VERSION ""

NS_ :

BS_:

BU_: EDS_F

VAL_TABLE_ Rolling_Counter_0x176 15 "Invalid";
VAL_TABLE_ BMS_HVLinkVol_MEAS 65535 "Invalid";
VAL_TABLE_ BMS_HVPackVol_MEAS 65535 "Invalid";
VAL_TABLE_ Rolling_Counter_0x215 15 "Invalid";
VAL_TABLE_ BMS_HWCrash_Sts 1 "Crash " 0 "No Crash";
VAL_TABLE_ BMS_HVIL_STS 2 "short to ground" 1 "Open & short to battery" 0 "Closed";
VAL_TABLE_ BMS_IGN_Sts 1 "ON " 0 "OFF";
VAL_TABLE_ BMS_Sys_STS 8 "Invalid" 7 "Failure, unable to operate" 6 "BCU Sleep mode" 5 "Successful Power Down" 4 "Power Down process" 3 "Successful Power Down of HV" 2 "Successful High Voltage Power Up" 1 "Self-check passes, can be high-voltage" 0 "Initialization of power on, self-checking";
VAL_TABLE_ BMS_HVOnOff_STS 3 "Fail to HV on " 2 "HV On " 1 "Precharge " 0 "HV Off";
VAL_TABLE_ BMS_Balance_STS 1 "active " 0 "Inactive";
VAL_TABLE_ BMS_BatBalance_ERR 1 "normal " 0 "Error";
VAL_TABLE_ BMS_ISU_Status 3 "Level3(<100 Ohms/V)" 2 "Level2(<200 Ohms/V)" 1 "Level1 <500 Ohms/V ~ >200 Ohms/V" 0 "Normal (> 500 Ohms/V)";
VAL_TABLE_ BMS_ERR_LEV 7 "Battery locked -Reserved" 6 "Fault, needs Shutdown and Wakeup" 5 "Emergency off condition" 4 "Delayed power down with FTTI" 3 "Power down without FTTI" 2 "Limp Home" 1 " Warning (any warning in system)" 0 "No error";
VAL_TABLE_ BMS_HV_Sts 4 "AC Charging" 3 "DC Charging" 2 "HV ON" 1 "Precharge" 0 "HV Off";
VAL_TABLE_ Rolling_Counter_0x375 15 "Invalid";
VAL_TABLE_ BMS_MainPosRelay_ERR 1 "normal " 0 "Error";
VAL_TABLE_ BMS_MainPosRelay_STS 4 "stuck open" 3 "stuck closed" 2 "closed" 1 "open" 0 "reserved";
VAL_TABLE_ BMS_PreChgRelay_ERR 1 "normal " 0 "error";
VAL_TABLE_ BMS_PreChgRelay_STS 4 "stuck open" 3 "stuck closed" 2 "closed" 1 "open" 0 "reserved";
VAL_TABLE_ BMS_TotalNegRelay_STS 4 "stuck open" 3 "stuck closed" 2 "closed" 1 "open" 0 "reserved";
VAL_TABLE_ BMS_TotalNegRelay_ERR 1 "normal " 0 "Error";
VAL_TABLE_ EDS_bus_Volt_FWD 16383 "Invalid";
VAL_TABLE_ EDS_bus_Curr_FWD 65535 "Invalid";
VAL_TABLE_ EDS_HVIL_STS_FWD 3 "short to ground" 2 "short to battery" 1 "Open" 0 "Closed";
VAL_TABLE_ Rolling_Counter_0x1F8 15 "Invalid";
VAL_TABLE_ EDS_output_trq_FR 65535 "Invalid";
VAL_TABLE_ EDS_output_trqValid_FR 1 "valid" 0 "invalid";
VAL_TABLE_ EDS_Spd_FR 65535 "Invalid";
VAL_TABLE_ EDS_SpdValid_FR 1 "valid" 0 "invalid";
VAL_TABLE_ EDS_MotorDriveSts_FR 3 "Invaild" 2 "regen control" 1 "Drive control" 0 "Zero control";
VAL_TABLE_ EDS_Work_STS_FR 15 "invaild" 14 "power off" 13 "Failure" 12 "after run" 11 "shut down" 5 "HVReady" 4 "normal" 3 "precharge" 2 "standby" 1 "init" 0 "default";
VAL_TABLE_ EDS_powoff_req_FR 1 "(Request high voltage power down)" 0 "(No request)";
VAL_TABLE_ Rolling_Counter_0x2A8 15 "Invalid";
VAL_TABLE_ EDS_MotorSerialNum_FWD 0 "Invalid";
VAL_TABLE_ EDS_MinTrq_FWD 65535 "Invalid";
VAL_TABLE_ EDS_MaxTrq_FWD 65535 "Invalid";
VAL_TABLE_ EDS_MotTemp_MEAS_EDS_FWD 255 "Invalid";
VAL_TABLE_ EDS_MotTemp_MEAS_EDS_valid_FWD 1 "valid" 0 "invalid";
VAL_TABLE_ EDS_temp_FWD 255 "Invalid";
VAL_TABLE_ EDS_tempValid_FWD 1 "valid" 0 "invalid";
VAL_TABLE_ EDS_disxhg_st_FWD 3 "Finished Active Discharge" 2 "Failed Active Discharge" 1 "Active Discharge" 0 "No Active Discharge";
VAL_TABLE_ EDS_IGBTState_FWD 0 "FreeWheel" 1 "Up Bridge ASC" 2 "Down Bridge ASC" 3 "Normal Run";
VAL_TABLE_ EDS_DampingState_FWD 0 "Damping disable" 1 "Damping active";
VAL_TABLE_ EDS_CoolFlowrate_DMD_FWD 255 "Invalid";
VAL_TABLE_ EDS_FailGrade_ERR_FWD 7 "Invaild" 6 "Invaild" 5 "Fifth Fault,Delayed power off" 4 "Forth Fault,ZeroTorque" 3 "Third Fault,Limp" 2 "Second Fault，Limited power" 1 "First-Level warning" 0 "No fault";
VAL_TABLE_ EDS_MotOverTempAlarm_FWD 1 "Error" 0 "Normal";
VAL_TABLE_ EDS_MotOverTempFault_FWD 1 "Error" 0 "Normal";
VAL_TABLE_ EDS_MotTempSenFault_FWD 1 "Error" 0 "Normal";
VAL_TABLE_ EDS_EDSOverTempUFault_FWD 1 "Error" 0 "Normal";
VAL_TABLE_ EDS_EDSOverTempVFault_FWD 1 "Error" 0 "Normal";
VAL_TABLE_ EDS_EDSOverTempWFault_FWD 1 "Error" 0 "Normal";
VAL_TABLE_ EDS_EDSOverTempAlarm_FWD 1 "Error" 0 "Normal";
VAL_TABLE_ EDS_TCoolantOvHi_FWD 1 "Error" 0 "Normal";
VAL_TABLE_ EDS_EDSTempCmpAlarm_FWD 1 "Error" 0 "Normal";
VAL_TABLE_ EDS_EDSPhaOvCurentHWFault_FWD 1 "Error" 0 "Normal";
VAL_TABLE_ EDS_EDSphaOffCalFault_FWD 1 "Error" 0 "Normal";
VAL_TABLE_ EDS_EDSOverIdcLnkAlarm_FWD 1 "Error" 0 "Normal";
VAL_TABLE_ EDS_EDSHVOverVoltageAlarm_FWD 1 "Error" 0 "Normal";
VAL_TABLE_ EDS_EDSHVOverVoltageFault_FWD 1 "Error" 0 "Normal";
VAL_TABLE_ EDS_EDSHVUnderVoltageAlarm_FWD 1 "Error" 0 "Normal";
VAL_TABLE_ EDS_EDSHVUnderVoltageFault_FWD 1 "Error" 0 "Normal";
VAL_TABLE_ EDS_RunToDischaErr_FWD 1 "Error" 0 "Normal";
VAL_TABLE_ EDS_12VOverVoltageAlarm_FWD 1 "Error" 0 "Normal";
VAL_TABLE_ EDS_12VUnderVoltageAlarm_FWD 1 "Error" 0 "Normal";
VAL_TABLE_ EDS_MotOverAlarm_FWD 1 "Error" 0 "Normal";
VAL_TABLE_ EDS_MotOverFault_FWD 1 "Error" 0 "Normal";
VAL_TABLE_ EDS_iDcLnkOvCLimFail_FWD 1 "Error" 0 "Normal";
VAL_TABLE_ EDS_MotBlockedFault_FWD 1 "Error" 0 "Normal";
VAL_TABLE_ EDS_RSLErr_FWD 1 "Error" 0 "Normal";
VAL_TABLE_ EDS_MotTrqLimFault_FWD 1 "Error" 0 "Normal";
VAL_TABLE_ EDS_ResolverOffsetAngle_FWD 1 "Error" 0 "Normal";
VAL_TABLE_ EDS_EDSDisChgFault_FWD 1 "Error" 0 "Normal";
VAL_TABLE_ EDS_IGBTFault_FWD 1 "Error" 0 "Normal";
VAL_TABLE_ EDS_CANBusoffFault_FWD 1 "Error" 0 "Normal";
VAL_TABLE_ EDS_TDrvBoardOvHiWarn_FWD 1 "Error" 0 "Normal";
VAL_TABLE_ EDS_TIGBTOvHiFault_FWD 1 "Error" 0 "Normal";
VAL_TABLE_ EDS_TIGBTOvHiWarn_FWD 1 "Error" 0 "Normal";
VAL_TABLE_ EDS_IOHWABSampFail_FWD 1 "Error" 0 "Normal";
VAL_TABLE_ EDS_EDSOpenFault_FWD 1 "Error" 0 "Normal";
VAL_TABLE_ EDS_MotorOpenFault_FWD 1 "Error" 0 "Normal";
VAL_TABLE_ EDS_EmacBlkdWarn_FWD 1 "Error" 0 "Normal";
VAL_TABLE_ EDS_VerMatchFailureErr_FWD 1 "Error" 0 "Normal";
VAL_TABLE_ EDS_DiashCirNoPsblErr_FWD 1 "Error" 0 "Normal";
VAL_TABLE_ EDS_OperOutdRngErr_FWD 1 "Error" 0 "Normal";
VAL_TABLE_ EDS_PhaseLossFaultErr_FWD 1 "Error" 0 "Normal";
VAL_TABLE_ EDS_CPLDFault_FWD 1 "Error" 0 "Normal";
VAL_TABLE_ EDS_CPLDFaultBaseSpd_FWD 1 "Error" 0 "Normal";
VAL_TABLE_ EDS_IOHWABNen33Fail_FWD 1 "Error" 0 "Normal";
VAL_TABLE_ EDS_HvMcuSlightFault_RWD 1 "Error" 0 "Normal";
VAL_TABLE_ EDS_HvMcuSevFault_FWD 1 "Error" 0 "Normal";
VAL_TABLE_ EDS_EDSPhaSampHWFault_FWD 1 "Error" 0 "Normal";
VAL_TABLE_ EDS_IsOvHiErr_FWD 1 "Error" 0 "Normal";
VAL_TABLE_ EDS_CanRollingCounterErr_FWD 1 "Error" 0 "Normal";
VAL_TABLE_ EDS_CanTimeoutErr_FWD 1 "Error" 0 "Normal";
VAL_TABLE_ EDS_CrashFault_FWD 1 "Error" 0 "Normal";
VAL_TABLE_ Rolling_Counter_0x229 15 "Invalid";
VAL_TABLE_ VCU_EDS_TargetTqMin_FWD 1023 "Invalid";
VAL_TABLE_ VCU_EDS_StsModeReq_FWD 15 "invaild" 14 "power off" 13 "Failure" 12 "after run" 11 "shut down" 5 "HVReady" 4 "normal" 3 "precharge" 2 "standby" 1 "init" 0 "default";
VAL_TABLE_ VCU_EDS_demtrq_FWD 4095 "Invalid";
VAL_TABLE_ VCU_EDS_demtrqValid_FWD 0 "Valid" 1 "Invalid";
VAL_TABLE_ VCU_EDS_TargetTqMax_FWD 1023 "Invalid";
VAL_TABLE_ VCU_EDS_CreepFlg_FWD 1 "Enable" 0 "Disable";
VAL_TABLE_ VCU_EDS_HILLHoldFlg_FWD 1 "Enable" 0 "Disable";
VAL_TABLE_ VCU_PTC_RelaySts 1 "close" 0 "open";
VAL_TABLE_ VCU_EACEnbReq 1 "Enable" 0 "Disable";
VAL_TABLE_ VCU_EACAllowedPower 1023 "Invalid";
VAL_TABLE_ VCU_EAC_CompSpdReq 16383 "Invaild";
VAL_TABLE_ Rolling_Counter_0x20C 15 "Invalid";
VAL_TABLE_ IPC_ODO 1048575 "Invalid";
VAL_TABLE_ IPC_TripA 65535 "Invalid";
VAL_TABLE_ IPC_AverageSpeedTripA 4095 "Invalid";
VAL_TABLE_ IPC_AverageConsumptionTripA 1023 "Invalid";
VAL_TABLE_ IPC_ParkBrakeSts 3 "Invalid" 2 "Reserved" 1 "Applied" 0 "Released";
VAL_TABLE_ IPC_VehSpd 32767 "Invalid";
VAL_TABLE_ IPC_Sec 63 "Invalid";
VAL_TABLE_ IPC_Min 63 "Invalid";
VAL_TABLE_ IPC_Hour 31 "Invalid";
VAL_TABLE_ IPC_Day 31 "Invalid";
VAL_TABLE_ IPC_Month 15 "Invalid";
VAL_TABLE_ IPC_Year 255 "Invalid";
VAL_TABLE_ IPC_SelfCheckStatus 1 "self-check finish" 0 "self-checking";
VAL_TABLE_ Rolling_Counter_0x432 15 "Invalid";
VAL_TABLE_ MHU_FOTA_State 0 "INIT" 1 "NORMAL" 2 "FOTA FLASHING" 3 "FOTA-SUSPENDED" 4 "FAIL-SAFE-ERROR" 5 "SHUTDOWN" 6 "REMOTE DIAGNOSTICS" 7 "Invalid";
VAL_TABLE_ CCU_TemperatureGearSts 63 "Invalid" 16 "level 8" 15 "level 7" 14 "level 6" 13 "level 5" 12 "level 4" 11 "level 3" 10 "level 2" 9 "level 1" 8 "level 8" 7 "level 7" 6 "level 6" 5 "level 5" 4 "level 4" 3 "level 3" 2 "level 2" 1 "level 1" 0 "Inactive";
VAL_TABLE_ CCU_BlowMode_Sts 7 "Invalid" 6 "Reserve" 4 "Foot and window" 3 "Foot" 2 "Foot and Face" 1 "Face" 0 "OFF";
VAL_TABLE_ CCU_Circulation_Sts 1 "Internal circulation" 0 "Outer circulation";
VAL_TABLE_ CCU_AC_Req 3 "Invalid" 2 "Reserved" 1 "Requset" 0 "No requset";
VAL_TABLE_ CCU_AC_Sts 1 "ON" 0 "OFF";
VAL_TABLE_ CCU_BlowerLevelSts 8 "level 8" 7 "level 7" 6 "level 6" 5 "level 5" 4 "level 4" 3 "level 3" 2 "level 2" 1 "level 1" 0 "OFF";
VAL_TABLE_ CCU_FrontDefrostSts 1 "On" 0 "Off";
VAL_TABLE_ CCU_PTC_Req 3 "Invalid" 2 "Reserved" 1 "Requset" 0 "No requset";
VAL_TABLE_ CCU_PTC_Temperature 1023 "Invaild";
VAL_TABLE_ CCU_CompSpdMEAS_Comp 8191 "Invalid";
VAL_TABLE_ CCU_PollutionSts 1 "ON" 0 "OFF";
VAL_TABLE_ CCU_ExternalTemperature 255 "Invaild";
VAL_TABLE_ CCU_evaporator_Temperature 31 "Invalid";
VAL_TABLE_ CCU_ExternalTemperatureFailSts 1 "invalid" 0 "valid";
VAL_TABLE_ Rolling_Counter_0x112 15 "Invalid";
VAL_TABLE_ STAT_Terminal 7 "Signal invalid" 6 "Reserved" 5 "Reserved" 4 "SW update OTA (Not used in VFe34)" 3 "Engine start (eMotor running)" 2 "ON (Driver Present)" 1 "ACC (Park)" 0 "OFF(Comfort Enable)";
VAL_TABLE_ STAT_CL30s_L_Reserved 3 "Signal invalid" 2 "Failure" 1 "ON" 0 "OFF";
VAL_TABLE_ Rolling_Counter_0x10a 15 "Invalid";
VAL_TABLE_ BCM_LVTop_up 1 "start Top up" 0 "stop Top up";
VAL_TABLE_ Rolling_Counter_0x85 15 "Invalid";
VAL_TABLE_ ACM_Crash_Sts 3 "Invalid Value" 2 "Invalid Value" 1 "Crash_Detected" 0 "No_Event";
VAL_TABLE_ ACM_Airbag_Deployment_Status 3 "Invalid Value" 2 "Invalid Value" 1 "Airbag_Deployment" 0 "No_Airbag_Deployment";
VAL_TABLE_ ACM_Crash_Intensity 7 "Invalid_Value" 6 "Invalid_Value" 5 "Invalid_Value" 4 "Invalid_Value" 3 "Crash_Intensity_3" 2 "Crash_Intensity_2" 1 "Crash_Intensity_1" 0 "No_Crash";
VAL_TABLE_ ACM_Front_Crash 3 "Invalid Value" 2 "Invalid Value" 1 "Front_Crash_Detected" 0 "No_Event";
VAL_TABLE_ ACM_DriverSide_Crash 3 "Invalid Value" 2 "Invalid Value" 1 "Driverside_Crash_Detected" 0 "No_Event";
VAL_TABLE_ ACM_PassSide_Crash 3 "Invalid Value" 2 "Invalid Value" 1 "PassSide_Crash_Detected" 0 "No_Event";
VAL_TABLE_ ACM_Rear_Crash 3 "Invalid Value" 2 "Invalid Value" 1 "Rear_Crash_Detected" 0 "No_Event";
VAL_TABLE_ ACM_Rollover_Crash 3 "Invalid Value" 2 "Invalid Value" 1 "Rollover_Crash_Detected" 0 "No_Event";
VAL_TABLE_ Rolling_Counter_0x342 15 "Invalid";
VAL_TABLE_ ABS_LRWhlSpdRaw 32767 "Invalid";
VAL_TABLE_ ABS_LRWhlSpdRawValid 1 "Valid" 0 "Invalid";
VAL_TABLE_ ABS_RRWhlSpdRaw 32767 "Invalid";
VAL_TABLE_ ABS_RRWhlSpdRawValid 1 "Valid" 0 "Invalid";
VAL_TABLE_ ABS_VehSpd 32767 "Invalid";
VAL_TABLE_ ABS_VehSpdValid 1 "Valid" 0 "Invalid";
VAL_TABLE_ RollingCounter_0x95 15 "Invalid";
VAL_TABLE_ ABS_Active 3 "Signal invalid" 2 "Reserved" 1 "Active" 0 "Inactive";
VAL_TABLE_ ASR_Active 3 "Signal invalid" 2 "Reserved" 1 "Active" 0 "Inactive";
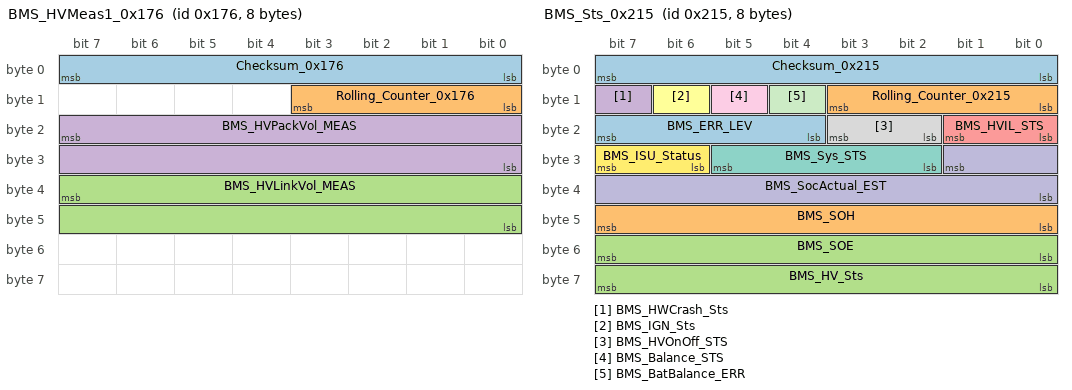
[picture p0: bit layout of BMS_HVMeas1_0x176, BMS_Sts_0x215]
BO_ 374 BMS_HVMeas1_0x176: 8 Vector__XXX
 SG_ Checksum_0x176 : 7|8@0+ (1,0) [0|255] "" EDS_F
 SG_ Rolling_Counter_0x176 : 11|4@0+ (1,0) [0|15] "" EDS_F
 SG_ BMS_HVLinkVol_MEAS : 39|16@0+ (0.1,0) [0|800] "V" Vector__XXX
 SG_ BMS_HVPackVol_MEAS : 23|16@0+ (0.1,0) [0|800] "V" EDS_F
BO_ 533 BMS_Sts_0x215: 8 Vector__XXX
 SG_ Checksum_0x215 : 7|8@0+ (1,0) [0|255] "" EDS_F
 SG_ Rolling_Counter_0x215 : 11|4@0+ (1,0) [0|15] "" EDS_F
 SG_ BMS_SOE : 55|8@0+ (0.5,0) [0|100] "%" Vector__XXX
 SG_ BMS_HWCrash_Sts : 15|1@0+ (1,0) [0|1] "" Vector__XXX
 SG_ BMS_HVIL_STS : 17|2@0+ (1,0) [0|3] "" EDS_F
 SG_ BMS_IGN_Sts : 14|1@0+ (1,0) [0|1] "" EDS_F
 SG_ BMS_Sys_STS : 29|4@0+ (1,0) [0|15] "" EDS_F
 SG_ BMS_HVOnOff_STS : 19|2@0+ (1,0) [0|3] "" EDS_F
 SG_ BMS_Balance_STS : 13|1@0+ (1,0) [0|1] "" EDS_F
 SG_ BMS_SocActual_EST : 25|10@0+ (0.1,0) [0|100] "percent" EDS_F
 SG_ BMS_BatBalance_ERR : 12|1@0+ (1,0) [0|1] "" EDS_F
 SG_ BMS_ISU_Status : 31|2@0+ (1,0) [0|3] "" EDS_F
 SG_ BMS_ERR_LEV : 23|4@0+ (1,0) [0|15] "" EDS_F
 SG_ BMS_SOH : 47|8@0+ (0.5,0) [0|100] "%" EDS_F
 SG_ BMS_HV_Sts : 63|8@0+ (1,0) [0|255] "" Vector__XXX
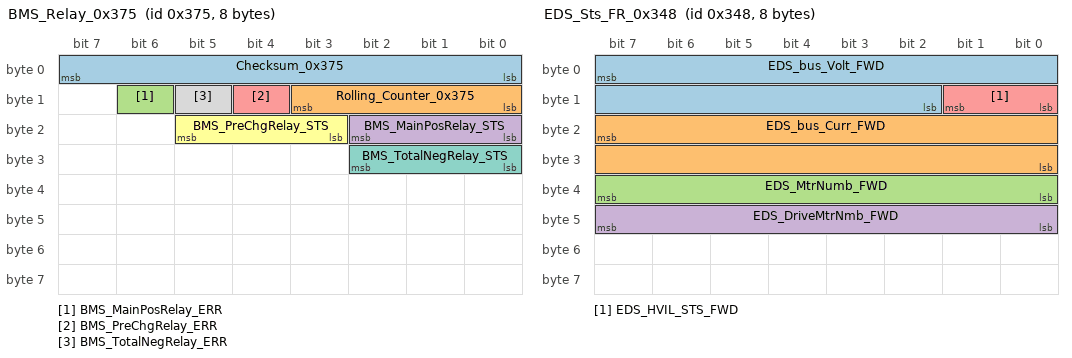
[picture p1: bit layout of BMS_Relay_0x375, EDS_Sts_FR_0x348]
BO_ 885 BMS_Relay_0x375: 8 Vector__XXX
 SG_ Checksum_0x375 : 7|8@0+ (1,0) [0|255] "" EDS_F
 SG_ Rolling_Counter_0x375 : 11|4@0+ (1,0) [0|15] "" EDS_F
 SG_ BMS_MainPosRelay_ERR : 14|1@0+ (1,0) [0|1] "" EDS_F
 SG_ BMS_MainPosRelay_STS : 18|3@0+ (1,0) [0|7] "" EDS_F
 SG_ BMS_PreChgRelay_ERR : 12|1@0+ (1,0) [0|1] "" Vector__XXX
 SG_ BMS_PreChgRelay_STS : 21|3@0+ (1,0) [0|7] "" Vector__XXX
 SG_ BMS_TotalNegRelay_STS : 26|3@0+ (1,0) [0|7] "" Vector__XXX
 SG_ BMS_TotalNegRelay_ERR : 13|1@0+ (1,0) [0|1] "" Vector__XXX
BO_ 840 EDS_Sts_FR_0x348: 8 EDS_F
 SG_ EDS_bus_Volt_FWD : 7|14@0+ (0.1,0) [0|1000] "V" Vector__XXX
 SG_ EDS_bus_Curr_FWD : 23|16@0+ (0.1,-1000) [-1000|1000] "A" Vector__XXX
 SG_ EDS_MtrNumb_FWD : 39|8@0+ (1,0) [0|255] "" Vector__XXX
 SG_ EDS_DriveMtrNmb_FWD : 47|8@0+ (1,0) [0|255] "" Vector__XXX
 SG_ EDS_HVIL_STS_FWD : 9|2@0+ (1,0) [0|3] "" Vector__XXX
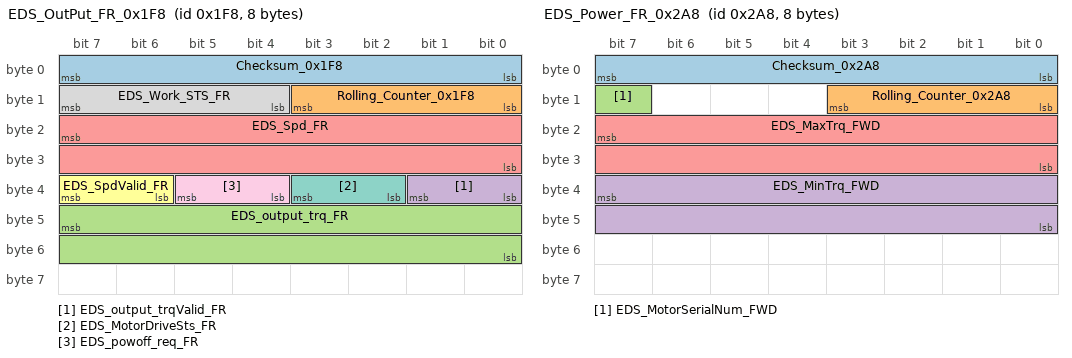
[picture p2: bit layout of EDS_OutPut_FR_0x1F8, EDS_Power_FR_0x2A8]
BO_ 504 EDS_OutPut_FR_0x1F8: 8 EDS_F
 SG_ Checksum_0x1F8 : 7|8@0+ (1,0) [0|255] "" Vector__XXX
 SG_ Rolling_Counter_0x1F8 : 11|4@0+ (1,0) [0|15] "" Vector__XXX
 SG_ EDS_output_trq_FR : 47|16@0+ (1,-2000) [-2000|2000] "Nm" Vector__XXX
 SG_ EDS_output_trqValid_FR : 33|2@0+ (1,0) [0|1] "" Vector__XXX
 SG_ EDS_Spd_FR : 23|16@0+ (1,-20000) [-20000|20000] "rpm" Vector__XXX
 SG_ EDS_SpdValid_FR : 39|2@0+ (1,0) [0|1] "" Vector__XXX
 SG_ EDS_MotorDriveSts_FR : 35|2@0+ (1,0) [0|3] "" Vector__XXX
 SG_ EDS_Work_STS_FR : 15|4@0+ (1,0) [0|15] "" Vector__XXX
 SG_ EDS_powoff_req_FR : 37|2@0+ (1,0) [0|1] "" Vector__XXX
BO_ 680 EDS_Power_FR_0x2A8: 8 EDS_F
 SG_ Checksum_0x2A8 : 7|8@0+ (1,0) [0|255] "" Vector__XXX
 SG_ Rolling_Counter_0x2A8 : 11|4@0+ (1,0) [0|15] "" Vector__XXX
 SG_ EDS_MotorSerialNum_FWD : 15|1@0+ (1,0) [0|1] "" Vector__XXX
 SG_ EDS_MinTrq_FWD : 39|16@0+ (1,-2000) [-2000|2000] "Nm" Vector__XXX
 SG_ EDS_MaxTrq_FWD : 23|16@0+ (1,-2000) [-2000|2000] "Nm" Vector__XXX
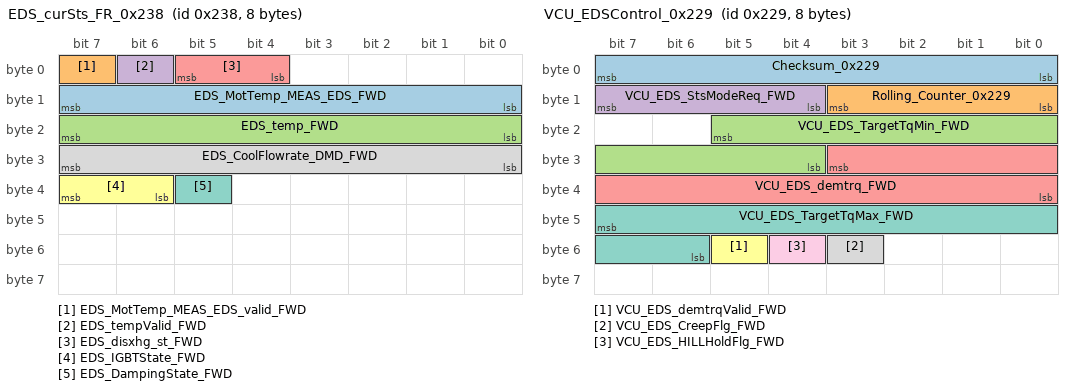
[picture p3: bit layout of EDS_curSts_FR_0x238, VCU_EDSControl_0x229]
BO_ 568 EDS_curSts_FR_0x238: 8 EDS_F
 SG_ EDS_MotTemp_MEAS_EDS_FWD : 15|8@0+ (1,-40) [-40|215] "degree" Vector__XXX
 SG_ EDS_MotTemp_MEAS_EDS_valid_FWD : 7|1@0+ (1,0) [0|1] "" Vector__XXX
 SG_ EDS_temp_FWD : 23|8@0+ (1,-40) [-40|215] "degree" Vector__XXX
 SG_ EDS_tempValid_FWD : 6|1@0+ (1,0) [0|1] "" Vector__XXX
 SG_ EDS_disxhg_st_FWD : 5|2@0+ (1,0) [0|3] "" Vector__XXX
 SG_ EDS_IGBTState_FWD : 39|2@0+ (1,0) [0|3] "" Vector__XXX
 SG_ EDS_DampingState_FWD : 37|1@0+ (1,0) [0|1] "" Vector__XXX
 SG_ EDS_CoolFlowrate_DMD_FWD : 31|8@0+ (0.1,0) [0|25.4] "L/min" Vector__XXX
BO_ 1080 EDS_Error_FR_0x438: 8 EDS_F
 SG_ EDS_FailNum_ERR_FWD : 7|8@0+ (1,0) [0|255] "" Vector__XXX
 SG_ EDS_FailGrade_ERR_FWD : 10|3@0+ (1,0) [0|7] "" Vector__XXX
 SG_ EDS_MotOverTempAlarm_FWD : 11|1@0+ (1,0) [0|1] "" Vector__XXX
 SG_ EDS_MotOverTempFault_FWD : 12|1@0+ (1,0) [0|1] "" Vector__XXX
 SG_ EDS_MotTempSenFault_FWD : 13|1@0+ (1,0) [0|1] "" Vector__XXX
 SG_ EDS_EDSOverTempUFault_FWD : 14|1@0+ (1,0) [0|1] "" Vector__XXX
 SG_ EDS_EDSOverTempVFault_FWD : 15|1@0+ (1,0) [0|1] "" Vector__XXX
 SG_ EDS_EDSOverTempWFault_FWD : 16|1@0+ (1,0) [0|1] "" Vector__XXX
 SG_ EDS_EDSOverTempAlarm_FWD : 17|1@0+ (1,0) [0|1] "" Vector__XXX
 SG_ EDS_TCoolantOvHi_FWD : 18|1@0+ (1,0) [0|1] "" Vector__XXX
 SG_ EDS_EDSTempCmpAlarm_FWD : 19|1@0+ (1,0) [0|1] "" Vector__XXX
 SG_ EDS_EDSPhaOvCurentHWFault_FWD : 20|1@0+ (1,0) [0|1] "" Vector__XXX
 SG_ EDS_EDSphaOffCalFault_FWD : 21|1@0+ (1,0) [0|1] "" Vector__XXX
 SG_ EDS_EDSOverIdcLnkAlarm_FWD : 22|1@0+ (1,0) [0|1] "" Vector__XXX
 SG_ EDS_EDSHVOverVoltageAlarm_FWD : 23|1@0+ (1,0) [0|1] "" Vector__XXX
 SG_ EDS_EDSHVOverVoltageFault_FWD : 24|1@0+ (1,0) [0|1] "" Vector__XXX
 SG_ EDS_EDSHVUnderVoltageAlarm_FWD : 25|1@0+ (1,0) [0|1] "" Vector__XXX
 SG_ EDS_EDSHVUnderVoltageFault_FWD : 26|1@0+ (1,0) [0|1] "" Vector__XXX
 SG_ EDS_RunToDischaErr_FWD : 27|1@0+ (1,0) [0|1] "" Vector__XXX
 SG_ EDS_12VOverVoltageAlarm_FWD : 28|1@0+ (1,0) [0|1] "" Vector__XXX
 SG_ EDS_12VUnderVoltageAlarm_FWD : 29|1@0+ (1,0) [0|1] "" Vector__XXX
 SG_ EDS_MotOverAlarm_FWD : 30|1@0+ (1,0) [0|1] "" Vector__XXX
 SG_ EDS_MotOverFault_FWD : 31|1@0+ (1,0) [0|1] "" Vector__XXX
 SG_ EDS_iDcLnkOvCLimFail_FWD : 32|1@0+ (1,0) [0|1] "" Vector__XXX
 SG_ EDS_MotBlockedFault_FWD : 33|1@0+ (1,0) [0|1] "" Vector__XXX
 SG_ EDS_RSLErr_FWD : 34|1@0+ (1,0) [0|1] "" Vector__XXX
 SG_ EDS_MotTrqLimFault_FWD : 35|1@0+ (1,0) [0|1] "" Vector__XXX
 SG_ EDS_ResolverOffsetAngle_FWD : 36|1@0+ (1,0) [0|1] "" Vector__XXX
 SG_ EDS_EDSDisChgFault_FWD : 37|1@0+ (1,0) [0|1] "" Vector__XXX
 SG_ EDS_IGBTFault_FWD : 38|1@0+ (1,0) [0|1] "" Vector__XXX
 SG_ EDS_CANBusoffFault_FWD : 39|1@0+ (1,0) [0|1] "" Vector__XXX
 SG_ EDS_TDrvBoardOvHiWarn_FWD : 40|1@0+ (1,0) [0|1] "" Vector__XXX
 SG_ EDS_TIGBTOvHiFault_FWD : 41|1@0+ (1,0) [0|1] "" Vector__XXX
 SG_ EDS_TIGBTOvHiWarn_FWD : 42|1@0+ (1,0) [0|1] "" Vector__XXX
 SG_ EDS_IOHWABSampFail_FWD : 43|1@0+ (1,0) [0|1] "" Vector__XXX
 SG_ EDS_EDSOpenFault_FWD : 44|1@0+ (1,0) [0|1] "" Vector__XXX
 SG_ EDS_MotorOpenFault_FWD : 45|1@0+ (1,0) [0|1] "" Vector__XXX
 SG_ EDS_EmacBlkdWarn_FWD : 47|1@0+ (1,0) [0|1] "" Vector__XXX
 SG_ EDS_VerMatchFailureErr_FWD : 48|1@0+ (1,0) [0|1] "" Vector__XXX
 SG_ EDS_DiashCirNoPsblErr_FWD : 49|1@0+ (1,0) [0|1] "" Vector__XXX
 SG_ EDS_OperOutdRngErr_FWD : 50|1@0+ (1,0) [0|1] "" Vector__XXX
 SG_ EDS_PhaseLossFaultErr_FWD : 51|1@0+ (1,0) [0|1] "" Vector__XXX
 SG_ EDS_CPLDFault_FWD : 52|1@0+ (1,0) [0|1] "" Vector__XXX
 SG_ EDS_CPLDFaultBaseSpd_FWD : 53|1@0+ (1,0) [0|1] "" Vector__XXX
 SG_ EDS_IOHWABNen33Fail_FWD : 54|1@0+ (1,0) [0|1] "" Vector__XXX
 SG_ EDS_HvMcuSlightFault_RWD : 55|1@0+ (1,0) [0|1] "" Vector__XXX
 SG_ EDS_HvMcuSevFault_FWD : 56|1@0+ (1,0) [0|1] "" Vector__XXX
 SG_ EDS_EDSPhaSampHWFault_FWD : 57|1@0+ (1,0) [0|1] "" Vector__XXX
 SG_ EDS_IsOvHiErr_FWD : 58|1@0+ (1,0) [0|1] "" Vector__XXX
 SG_ EDS_CanRollingCounterErr_FWD : 59|1@0+ (1,0) [0|1] "" Vector__XXX
 SG_ EDS_CanTimeoutErr_FWD : 60|1@0+ (1,0) [0|1] "" Vector__XXX
 SG_ EDS_CrashFault_FWD : 61|1@0+ (1,0) [0|1] "" Vector__XXX
BO_ 553 VCU_EDSControl_0x229: 8 Vector__XXX
 SG_ Checksum_0x229 : 7|8@0+ (1,0) [0|255] "" EDS_F
 SG_ Rolling_Counter_0x229 : 11|4@0+ (1,0) [0|15] "" EDS_F
 SG_ VCU_EDS_TargetTqMin_FWD : 21|10@0+ (1,-500) [-500|0] "Nm" EDS_F
 SG_ VCU_EDS_StsModeReq_FWD : 15|4@0+ (1,0) [0|15] "" EDS_F
 SG_ VCU_EDS_demtrq_FWD : 27|12@0+ (0.5,-500) [-500|500] "Nm" EDS_F
 SG_ VCU_EDS_demtrqValid_FWD : 53|1@0+ (1,0) [0|1] "" EDS_F
 SG_ VCU_EDS_TargetTqMax_FWD : 47|10@0+ (1,0) [0|500] "Nm" EDS_F
 SG_ VCU_EDS_CreepFlg_FWD : 51|1@0+ (1,0) [0|1] "" Vector__XXX
 SG_ VCU_EDS_HILLHoldFlg_FWD : 52|1@0+ (1,0) [0|1] "" Vector__XXX
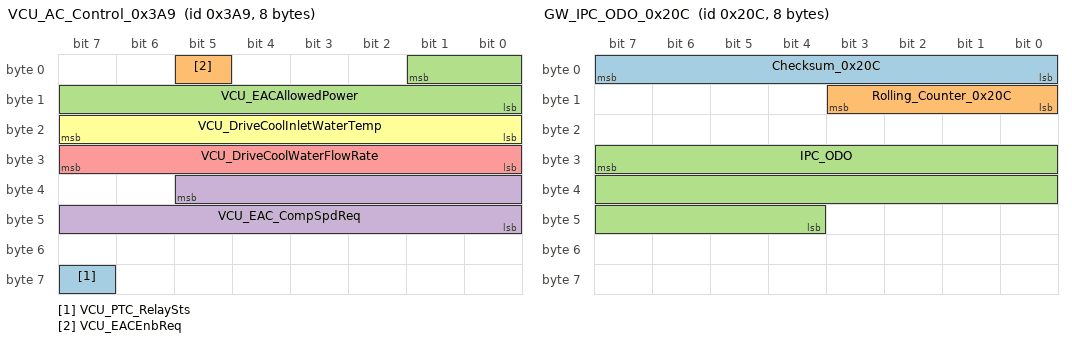
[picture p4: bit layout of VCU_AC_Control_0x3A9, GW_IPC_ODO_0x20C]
BO_ 937 VCU_AC_Control_0x3A9: 8 Vector__XXX
 SG_ VCU_PTC_RelaySts : 63|1@0+ (1,0) [0|1] "" Vector__XXX
 SG_ VCU_EACEnbReq : 5|1@0+ (1,0) [0|1] "" Vector__XXX
 SG_ VCU_EACAllowedPower : 1|10@0+ (0.1,0) [0|100] "KW" Vector__XXX
 SG_ VCU_EAC_CompSpdReq : 37|14@0+ (1,0) [0|16383] "rpm" Vector__XXX
 SG_ VCU_DriveCoolWaterFlowRate : 31|8@0+ (0.1,0) [0|25.4] "L/min" EDS_F
 SG_ VCU_DriveCoolInletWaterTemp : 23|8@0+ (1,-40) [-40|215] "degree" EDS_F
BO_ 524 GW_IPC_ODO_0x20C: 8 Vector__XXX
 SG_ Checksum_0x20C : 7|8@0+ (1,0) [0|255] "" EDS_F
 SG_ Rolling_Counter_0x20C : 11|4@0+ (1,0) [0|15] "" EDS_F
 SG_ IPC_ODO : 31|20@0+ (1,0) [0|999999] "km" EDS_F
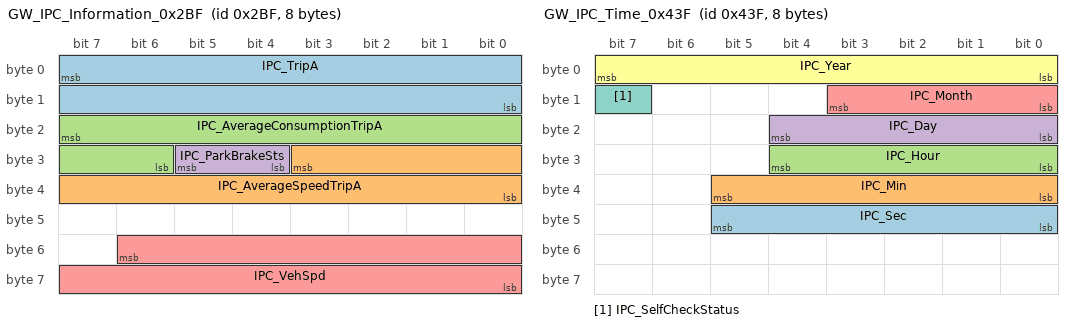
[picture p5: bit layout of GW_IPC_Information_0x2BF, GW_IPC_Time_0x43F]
BO_ 703 GW_IPC_Information_0x2BF: 8 Vector__XXX
 SG_ IPC_TripA : 7|16@0+ (0.1,0) [0|999.9] "km" Vector__XXX
 SG_ IPC_AverageSpeedTripA : 27|12@0+ (0.0625,0) [0|250] "km/h" Vector__XXX
 SG_ IPC_AverageConsumptionTripA : 23|10@0+ (0.1,0) [0|100] "kwh/100km" Vector__XXX
 SG_ IPC_ParkBrakeSts : 29|2@0+ (1,0) [0|3] "" Vector__XXX
 SG_ IPC_VehSpd : 54|15@0+ (0.01,0) [0|327.66] "kph" EDS_F
BO_ 1087 GW_IPC_Time_0x43F: 8 Vector__XXX
 SG_ IPC_Sec : 45|6@0+ (1,0) [0|59] "second" EDS_F
 SG_ IPC_Min : 37|6@0+ (1,0) [0|59] "min" EDS_F
 SG_ IPC_Hour : 28|5@0+ (1,0) [0|23] "hour" EDS_F
 SG_ IPC_Day : 20|5@0+ (1,0) [1|31] "" EDS_F
 SG_ IPC_Month : 11|4@0+ (1,0) [1|12] "" EDS_F
 SG_ IPC_Year : 7|8@0+ (1,2000) [2000|2255] "" EDS_F
 SG_ IPC_SelfCheckStatus : 15|1@0+ (1,0) [0|1] "" EDS_F
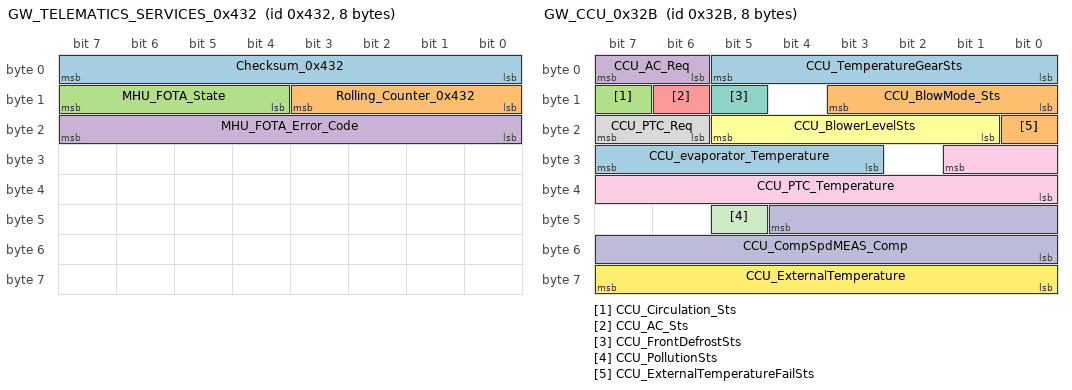
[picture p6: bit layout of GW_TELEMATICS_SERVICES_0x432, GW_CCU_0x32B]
BO_ 1074 GW_TELEMATICS_SERVICES_0x432: 8 Vector__XXX
 SG_ Checksum_0x432 : 7|8@0+ (1,0) [0|255] "" EDS_F
 SG_ Rolling_Counter_0x432 : 11|4@0+ (1,0) [0|14] "" EDS_F
 SG_ MHU_FOTA_State : 15|4@0+ (1,0) [0|14] "" EDS_F
 SG_ MHU_FOTA_Error_Code : 23|8@0+ (1,0) [0|255] "" EDS_F
BO_ 811 GW_CCU_0x32B: 8 Vector__XXX
 SG_ CCU_TemperatureGearSts : 5|6@0+ (1,0) [0|63] "" Vector__XXX
 SG_ CCU_BlowMode_Sts : 11|4@0+ (1,0) [0|15] "" Vector__XXX
 SG_ CCU_Circulation_Sts : 15|1@0+ (1,0) [0|1] "" Vector__XXX
 SG_ CCU_AC_Req : 7|2@0+ (1,0) [0|3] "" Vector__XXX
 SG_ CCU_AC_Sts : 14|1@0+ (1,0) [0|1] "" Vector__XXX
 SG_ CCU_BlowerLevelSts : 21|5@0+ (1,0) [0|9] "" Vector__XXX
 SG_ CCU_FrontDefrostSts : 13|1@0+ (1,0) [0|1] "" Vector__XXX
 SG_ CCU_PTC_Req : 23|2@0+ (1,0) [0|3] "" Vector__XXX
 SG_ CCU_PTC_Temperature : 25|10@0+ (0.1,0) [0|100] "°C" Vector__XXX
 SG_ CCU_CompSpdMEAS_Comp : 44|13@0+ (1,0) [0|8191] "rpm" Vector__XXX
 SG_ CCU_PollutionSts : 45|1@0+ (1,0) [0|1] "" Vector__XXX
 SG_ CCU_ExternalTemperature : 63|8@0+ (0.5,-40) [-40|87] "°C" EDS_F
 SG_ CCU_evaporator_Temperature : 31|5@0+ (1,-10) [-10|20] "°C" Vector__XXX
 SG_ CCU_ExternalTemperatureFailSts : 16|1@0+ (1,0) [0|1] "" EDS_F
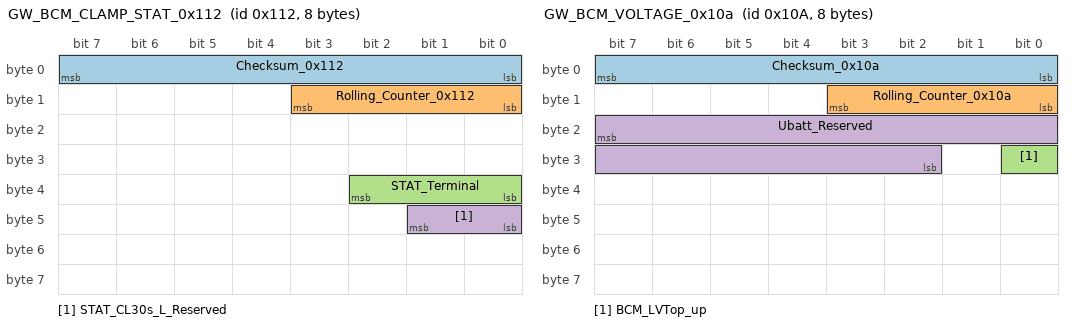
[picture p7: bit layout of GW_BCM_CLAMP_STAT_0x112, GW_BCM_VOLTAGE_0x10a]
BO_ 274 GW_BCM_CLAMP_STAT_0x112: 8 Vector__XXX
 SG_ Checksum_0x112 : 7|8@0+ (1,0) [0|255] "" EDS_F
 SG_ Rolling_Counter_0x112 : 11|4@0+ (1,0) [0|15] "" EDS_F
 SG_ STAT_Terminal : 34|3@0+ (1,0) [0|7] "Bit" EDS_F
 SG_ STAT_CL30s_L_Reserved : 41|2@0+ (1,0) [0|3] "Bit" Vector__XXX
BO_ 266 GW_BCM_VOLTAGE_0x10a: 8 Vector__XXX
 SG_ Checksum_0x10a : 7|8@0+ (1,0) [0|255] "" EDS_F
 SG_ Rolling_Counter_0x10a : 11|4@0+ (1,0) [0|15] "" EDS_F
 SG_ BCM_LVTop_up : 24|1@0+ (1,0) [0|1] "" Vector__XXX
 SG_ Ubatt_Reserved : 23|14@0+ (0.001,3) [3|18] "V" EDS_F
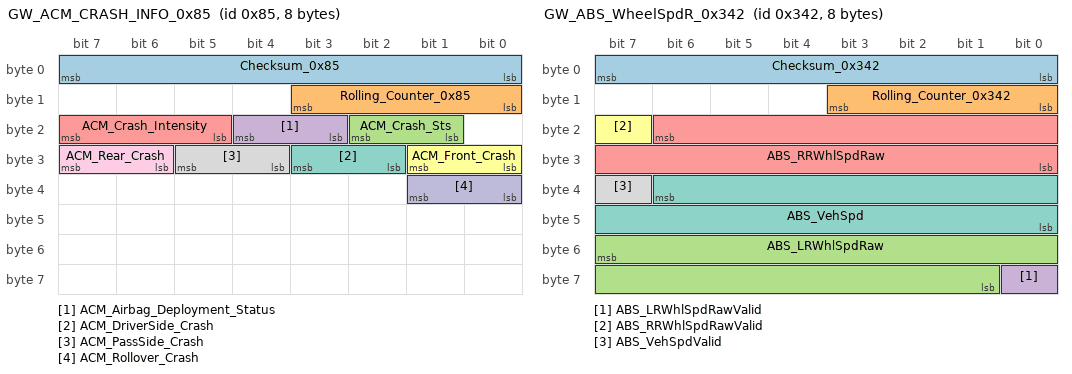
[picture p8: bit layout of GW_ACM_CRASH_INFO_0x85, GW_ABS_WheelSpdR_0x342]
BO_ 133 GW_ACM_CRASH_INFO_0x85: 8 Vector__XXX
 SG_ Checksum_0x85 : 7|8@0+ (1,0) [0|255] "" EDS_F
 SG_ Rolling_Counter_0x85 : 11|4@0+ (1,0) [0|15] "" EDS_F
 SG_ ACM_Crash_Sts : 18|2@0+ (1,0) [0|3] "" EDS_F
 SG_ ACM_Airbag_Deployment_Status : 20|2@0+ (1,0) [0|3] "" Vector__XXX
 SG_ ACM_Crash_Intensity : 23|3@0+ (1,0) [0|7] "" EDS_F
 SG_ ACM_Front_Crash : 25|2@0+ (1,0) [0|3] "" Vector__XXX
 SG_ ACM_DriverSide_Crash : 27|2@0+ (1,0) [0|3] "" Vector__XXX
 SG_ ACM_PassSide_Crash : 29|2@0+ (1,0) [0|3] "" Vector__XXX
 SG_ ACM_Rear_Crash : 31|2@0+ (1,0) [0|3] "" Vector__XXX
 SG_ ACM_Rollover_Crash : 33|2@0+ (1,0) [0|3] "" Vector__XXX
BO_ 834 GW_ABS_WheelSpdR_0x342: 8 Vector__XXX
 SG_ Checksum_0x342 : 7|8@0+ (1,0) [0|255] "" EDS_F
 SG_ Rolling_Counter_0x342 : 11|4@0+ (1,0) [0|15] "" EDS_F
 SG_ ABS_LRWhlSpdRaw : 55|15@0+ (0.01,0) [0|327.66] "kph" Vector__XXX
 SG_ ABS_LRWhlSpdRawValid : 56|1@0+ (1,0) [0|1] "" Vector__XXX
 SG_ ABS_RRWhlSpdRaw : 22|15@0+ (0.01,0) [0|327.66] "kph" Vector__XXX
 SG_ ABS_RRWhlSpdRawValid : 23|1@0+ (1,0) [0|1] "" Vector__XXX
 SG_ ABS_VehSpd : 38|15@0+ (0.01,0) [0|327.66] "kph" EDS_F
 SG_ ABS_VehSpdValid : 39|1@0+ (1,0) [0|1] "" EDS_F
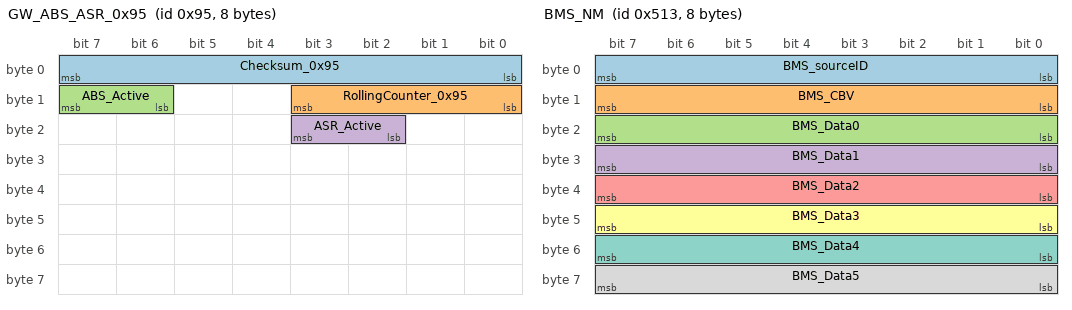
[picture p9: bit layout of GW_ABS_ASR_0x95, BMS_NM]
BO_ 149 GW_ABS_ASR_0x95: 8 Vector__XXX
 SG_ Checksum_0x95 : 7|8@0+ (1,0) [0|255] "" EDS_F
 SG_ RollingCounter_0x95 : 11|4@0+ (1,0) [0|14] "" EDS_F
 SG_ ABS_Active : 15|2@0+ (1,0) [0|3] "" EDS_F
 SG_ ASR_Active : 19|2@0+ (1,0) [0|3] "" EDS_F
BO_ 1299 BMS_NM: 8 Vector__XXX
 SG_ BMS_sourceID : 7|8@0+ (1,0) [0|255] "" EDS_F
 SG_ BMS_CBV : 15|8@0+ (1,0) [0|255] "" EDS_F
 SG_ BMS_Data0 : 23|8@0+ (1,0) [0|255] "" EDS_F
 SG_ BMS_Data1 : 31|8@0+ (1,0) [0|255] "" EDS_F
 SG_ BMS_Data2 : 39|8@0+ (1,0) [0|255] "" EDS_F
 SG_ BMS_Data3 : 47|8@0+ (1,0) [0|255] "" EDS_F
 SG_ BMS_Data4 : 55|8@0+ (1,0) [0|255] "" EDS_F
 SG_ BMS_Data5 : 63|8@0+ (1,0) [0|255] "" EDS_F
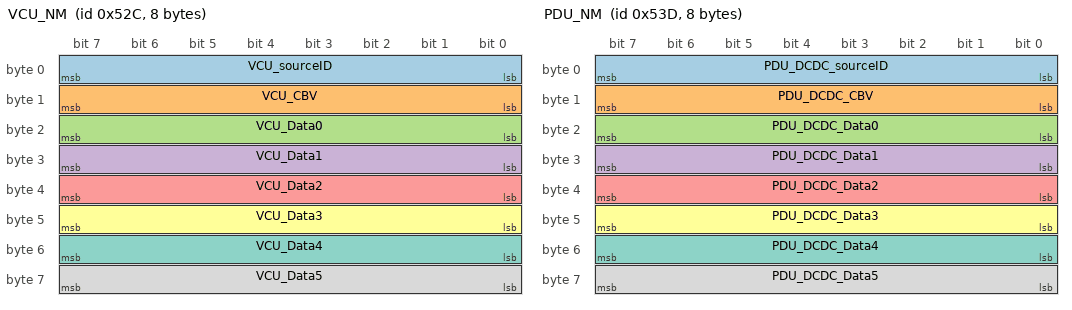
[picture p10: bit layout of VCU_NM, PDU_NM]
BO_ 1324 VCU_NM: 8 Vector__XXX
 SG_ VCU_sourceID : 7|8@0+ (1,0) [0|255] "" EDS_F
 SG_ VCU_CBV : 15|8@0+ (1,0) [0|255] "" EDS_F
 SG_ VCU_Data0 : 23|8@0+ (1,0) [0|255] "" EDS_F
 SG_ VCU_Data1 : 31|8@0+ (1,0) [0|255] "" EDS_F
 SG_ VCU_Data2 : 39|8@0+ (1,0) [0|255] "" EDS_F
 SG_ VCU_Data3 : 47|8@0+ (1,0) [0|255] "" EDS_F
 SG_ VCU_Data4 : 55|8@0+ (1,0) [0|255] "" EDS_F
 SG_ VCU_Data5 : 63|8@0+ (1,0) [0|255] "" EDS_F
BO_ 1341 PDU_NM: 8 Vector__XXX
 SG_ PDU_DCDC_sourceID : 7|8@0+ (1,0) [0|255] "" EDS_F
 SG_ PDU_DCDC_CBV : 15|8@0+ (1,0) [0|255] "" EDS_F
 SG_ PDU_DCDC_Data0 : 23|8@0+ (1,0) [0|255] "" EDS_F
 SG_ PDU_DCDC_Data1 : 31|8@0+ (1,0) [0|255] "" EDS_F
 SG_ PDU_DCDC_Data2 : 39|8@0+ (1,0) [0|255] "" EDS_F
 SG_ PDU_DCDC_Data3 : 47|8@0+ (1,0) [0|255] "" EDS_F
 SG_ PDU_DCDC_Data4 : 55|8@0+ (1,0) [0|255] "" EDS_F
 SG_ PDU_DCDC_Data5 : 63|8@0+ (1,0) [0|255] "" EDS_F
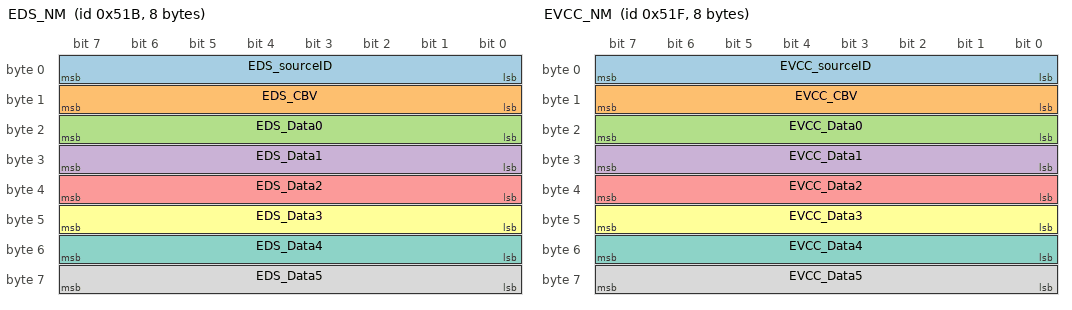
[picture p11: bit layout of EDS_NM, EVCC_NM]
BO_ 1307 EDS_NM: 8 EDS_F
 SG_ EDS_sourceID : 7|8@0+ (1,0) [0|255] "" Vector__XXX
 SG_ EDS_CBV : 15|8@0+ (1,0) [0|255] "" Vector__XXX
 SG_ EDS_Data0 : 23|8@0+ (1,0) [0|255] "" Vector__XXX
 SG_ EDS_Data1 : 31|8@0+ (1,0) [0|255] "" Vector__XXX
 SG_ EDS_Data2 : 39|8@0+ (1,0) [0|255] "" Vector__XXX
 SG_ EDS_Data3 : 47|8@0+ (1,0) [0|255] "" Vector__XXX
 SG_ EDS_Data4 : 55|8@0+ (1,0) [0|255] "" Vector__XXX
 SG_ EDS_Data5 : 63|8@0+ (1,0) [0|255] "" Vector__XXX
BO_ 1311 EVCC_NM: 8 Vector__XXX
 SG_ EVCC_sourceID : 7|8@0+ (1,0) [0|255] "" EDS_F
 SG_ EVCC_CBV : 15|8@0+ (1,0) [0|255] "" EDS_F
 SG_ EVCC_Data0 : 23|8@0+ (1,0) [0|255] "" EDS_F
 SG_ EVCC_Data1 : 31|8@0+ (1,0) [0|255] "" EDS_F
 SG_ EVCC_Data2 : 39|8@0+ (1,0) [0|255] "" EDS_F
 SG_ EVCC_Data3 : 47|8@0+ (1,0) [0|255] "" EDS_F
 SG_ EVCC_Data4 : 55|8@0+ (1,0) [0|255] "" EDS_F
 SG_ EVCC_Data5 : 63|8@0+ (1,0) [0|255] "" EDS_F
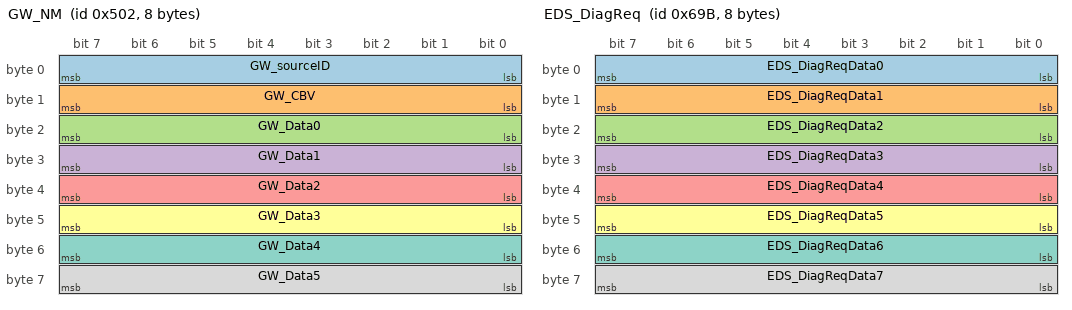
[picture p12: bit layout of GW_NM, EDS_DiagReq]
BO_ 1282 GW_NM: 8 Vector__XXX
 SG_ GW_sourceID : 7|8@0+ (1,0) [0|255] "" EDS_F
 SG_ GW_CBV : 15|8@0+ (1,0) [0|255] "" EDS_F
 SG_ GW_Data0 : 23|8@0+ (1,0) [0|255] "" EDS_F
 SG_ GW_Data1 : 31|8@0+ (1,0) [0|255] "" EDS_F
 SG_ GW_Data2 : 39|8@0+ (1,0) [0|255] "" EDS_F
 SG_ GW_Data3 : 47|8@0+ (1,0) [0|255] "" EDS_F
 SG_ GW_Data4 : 55|8@0+ (1,0) [0|255] "" EDS_F
 SG_ GW_Data5 : 63|8@0+ (1,0) [0|255] "" EDS_F
BO_ 1691 EDS_DiagReq: 8 Vector__XXX
 SG_ EDS_DiagReqData0 : 7|8@0+ (1,0) [0|255] "" EDS_F
 SG_ EDS_DiagReqData1 : 15|8@0+ (1,0) [0|255] "" EDS_F
 SG_ EDS_DiagReqData2 : 23|8@0+ (1,0) [0|255] "" EDS_F
 SG_ EDS_DiagReqData3 : 31|8@0+ (1,0) [0|255] "" EDS_F
 SG_ EDS_DiagReqData4 : 39|8@0+ (1,0) [0|255] "" EDS_F
 SG_ EDS_DiagReqData5 : 47|8@0+ (1,0) [0|255] "" EDS_F
 SG_ EDS_DiagReqData6 : 55|8@0+ (1,0) [0|255] "" EDS_F
 SG_ EDS_DiagReqData7 : 63|8@0+ (1,0) [0|255] "" EDS_F
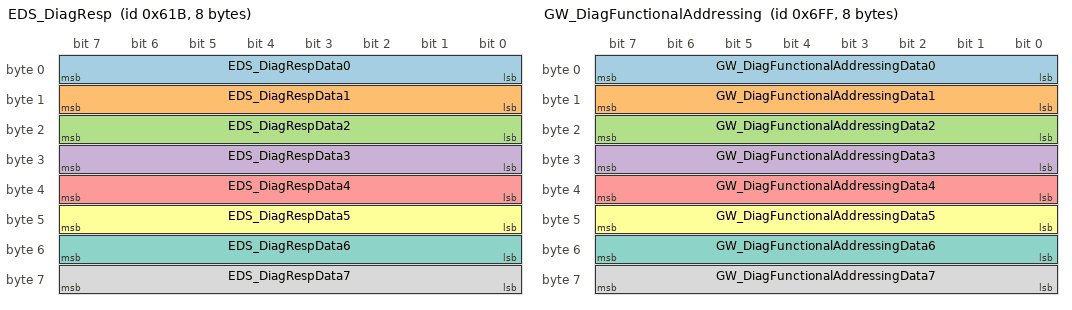
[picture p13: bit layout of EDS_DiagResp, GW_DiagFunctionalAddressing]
BO_ 1563 EDS_DiagResp: 8 EDS_F
 SG_ EDS_DiagRespData0 : 7|8@0+ (1,0) [0|255] "" Vector__XXX
 SG_ EDS_DiagRespData1 : 15|8@0+ (1,0) [0|255] "" Vector__XXX
 SG_ EDS_DiagRespData2 : 23|8@0+ (1,0) [0|255] "" Vector__XXX
 SG_ EDS_DiagRespData3 : 31|8@0+ (1,0) [0|255] "" Vector__XXX
 SG_ EDS_DiagRespData4 : 39|8@0+ (1,0) [0|255] "" Vector__XXX
 SG_ EDS_DiagRespData5 : 47|8@0+ (1,0) [0|255] "" Vector__XXX
 SG_ EDS_DiagRespData6 : 55|8@0+ (1,0) [0|255] "" Vector__XXX
 SG_ EDS_DiagRespData7 : 63|8@0+ (1,0) [0|255] "" Vector__XXX
BO_ 1791 GW_DiagFunctionalAddressing: 8 Vector__XXX
 SG_ GW_DiagFunctionalAddressingData0 : 7|8@0+ (1,0) [0|255] "" EDS_F
 SG_ GW_DiagFunctionalAddressingData1 : 15|8@0+ (1,0) [0|255] "" EDS_F
 SG_ GW_DiagFunctionalAddressingData2 : 23|8@0+ (1,0) [0|255] "" EDS_F
 SG_ GW_DiagFunctionalAddressingData3 : 31|8@0+ (1,0) [0|255] "" EDS_F
 SG_ GW_DiagFunctionalAddressingData4 : 39|8@0+ (1,0) [0|255] "" EDS_F
 SG_ GW_DiagFunctionalAddressingData5 : 47|8@0+ (1,0) [0|255] "" EDS_F
 SG_ GW_DiagFunctionalAddressingData6 : 55|8@0+ (1,0) [0|255] "" EDS_F
 SG_ GW_DiagFunctionalAddressingData7 : 63|8@0+ (1,0) [0|255] "" EDS_F
CM_ SG_ 374 Checksum_0x176 "Checksum";
CM_ SG_ 374 Rolling_Counter_0x176 "Rolling Counter";
CM_ SG_ 374 BMS_HVLinkVol_MEAS "Link Voltage";
CM_ SG_ 374 BMS_HVPackVol_MEAS "Pack Voltage";
CM_ SG_ 533 Checksum_0x215 "Checksum";
CM_ SG_ 533 Rolling_Counter_0x215 "Rolling Counter";
CM_ SG_ 533 BMS_SOE "BMS State Of Enegy";
CM_ SG_ 533 BMS_HWCrash_Sts "Battery Pack Hardware Crash signal Status";
CM_ SG_ 533 BMS_HVIL_STS "The HVIL state of BMS";
CM_ SG_ 533 BMS_IGN_Sts "the ignition signal status (on/off)";
CM_ SG_ 533 BMS_Sys_STS "BMS_Status(Self-test after BMS wake-up)";
CM_ SG_ 533 BMS_HVOnOff_STS "BMS High Voltage Status(BMS_HVOnOff_STS to be received by all modules,Used as a flash programming pre-condition (replacement for engine running)";
CM_ SG_ 533 BMS_Balance_STS "BMS Balance Status";
CM_ SG_ 533 BMS_SocActual_EST "Actual SOC";
CM_ SG_ 533 BMS_BatBalance_ERR "Battery Balance Error indicates Balancing switch is short or open";
CM_ SG_ 533 BMS_ISU_Status "Insulation status";
CM_ SG_ 533 BMS_ERR_LEV "BMS requesting VCU to operate at the limited operating strategy (LOS)";
CM_ SG_ 533 BMS_SOH "BMS State Of Health";
CM_ SG_ 533 BMS_HV_Sts "BMS High Voltage Status";
CM_ SG_ 885 Checksum_0x375 "Checksum";
CM_ SG_ 885 Rolling_Counter_0x375 "Rolling Counter";
CM_ SG_ 885 BMS_MainPosRelay_ERR "Main Position Relay Error";
CM_ SG_ 885 BMS_MainPosRelay_STS "Main Positive Relay Status";
CM_ SG_ 885 BMS_PreChgRelay_ERR "Precahrge relay is not working properly";
CM_ SG_ 885 BMS_PreChgRelay_STS "PreCharge Relay Status";
CM_ SG_ 885 BMS_TotalNegRelay_STS "Main Negative Relay Status";
CM_ SG_ 885 BMS_TotalNegRelay_ERR "Main Negative Relay Error";
CM_ SG_ 840 EDS_bus_Volt_FWD "Bus voltage of current EDS";
CM_ SG_ 840 EDS_bus_Curr_FWD "Bus current of current EDS";
CM_ SG_ 840 EDS_MtrNumb_FWD "Motor Number";
CM_ SG_ 840 EDS_DriveMtrNmb_FWD "DriveMotorNumber";
CM_ SG_ 840 EDS_HVIL_STS_FWD "FWD EDS HighVoltage state";
CM_ SG_ 504 Checksum_0x1F8 "Check sum";
CM_ SG_ 504 Rolling_Counter_0x1F8 "Rolling counter";
CM_ SG_ 504 EDS_output_trq_FR "Actual output torque of current EDS";
CM_ SG_ 504 EDS_output_trqValid_FR "Indicate the valid flag of current motor torque";
CM_ SG_ 504 EDS_Spd_FR "current motor speed";
CM_ SG_ 504 EDS_SpdValid_FR "Indicate the valid flag of current motor speed";
CM_ SG_ 504 EDS_MotorDriveSts_FR "The drive state of EDS";
CM_ SG_ 504 EDS_Work_STS_FR "EDS Work status";
CM_ SG_ 504 EDS_powoff_req_FR "If there is a serious failure in the running process of EDS, the high voltage of VCU will be requested";
CM_ SG_ 680 Checksum_0x2A8 "Checksum";
CM_ SG_ 680 Rolling_Counter_0x2A8 "Rolling counter";
CM_ SG_ 680 EDS_MotorSerialNum_FWD "FrontMotorSerialNumber";
CM_ SG_ 680 EDS_MinTrq_FWD "AllowMinTorque(long time min torque available)";
CM_ SG_ 680 EDS_MaxTrq_FWD "AllowMaxTorque(long time max torque available)";
CM_ SG_ 568 EDS_MotTemp_MEAS_EDS_FWD "Motor Temperature";
CM_ SG_ 568 EDS_MotTemp_MEAS_EDS_valid_FWD "Indicate the valid flag of MotorTemperature";
CM_ SG_ 568 EDS_temp_FWD "EDS current temperature";
CM_ SG_ 568 EDS_tempValid_FWD "Indicate the valid flag of EDS current temperature";
CM_ SG_ 568 EDS_disxhg_st_FWD "State of active discharge of EDS";
CM_ SG_ 568 EDS_IGBTState_FWD "FWD EDS IGBT State";
CM_ SG_ 568 EDS_DampingState_FWD "FWD EDS Damping state";
CM_ SG_ 568 EDS_CoolFlowrate_DMD_FWD "Coolant Florate demand from FWD EDS";
CM_ SG_ 1080 EDS_FailNum_ERR_FWD "FaultNumber";
CM_ SG_ 1080 EDS_FailGrade_ERR_FWD "Fault level of EDS system";
CM_ SG_ 1080 EDS_MotOverTempAlarm_FWD "Motor over temperture alarm";
CM_ SG_ 1080 EDS_MotOverTempFault_FWD "Motor over temperture fault";
CM_ SG_ 1080 EDS_MotTempSenFault_FWD "Motor temperature sensor fault";
CM_ SG_ 1080 EDS_EDSOverTempUFault_FWD "EDS Upha Over temperature fault";
CM_ SG_ 1080 EDS_EDSOverTempVFault_FWD "EDS Vpha Over temperature fault";
CM_ SG_ 1080 EDS_EDSOverTempWFault_FWD "EDS Wpha Over temperature fault";
CM_ SG_ 1080 EDS_EDSOverTempAlarm_FWD "EDS over temperture alarm";
CM_ SG_ 1080 EDS_TCoolantOvHi_FWD "Alarm  when Cooling water temperature is too high";
CM_ SG_ 1080 EDS_EDSTempCmpAlarm_FWD "EDS temp offset checkout alarm";
CM_ SG_ 1080 EDS_EDSPhaOvCurentHWFault_FWD "Phase Current Overcurrent hardware fault";
CM_ SG_ 1080 EDS_EDSphaOffCalFault_FWD "EDS phase Current Offset Calibration Fault";
CM_ SG_ 1080 EDS_EDSOverIdcLnkAlarm_FWD "EDS IdcLnk Overcurrent alarm";
CM_ SG_ 1080 EDS_EDSHVOverVoltageAlarm_FWD "EDS high voltage over voltage alarm";
CM_ SG_ 1080 EDS_EDSHVOverVoltageFault_FWD "EDS high voltage over voltage fault";
CM_ SG_ 1080 EDS_EDSHVUnderVoltageAlarm_FWD "EDS high voltage under voltage alarm";
CM_ SG_ 1080 EDS_EDSHVUnderVoltageFault_FWD "EDS high voltage under voltage fault";
CM_ SG_ 1080 EDS_RunToDischaErr_FWD "Stateflow fail to enter avtive discharge";
CM_ SG_ 1080 EDS_12VOverVoltageAlarm_FWD "12V Power over voltage alarm";
CM_ SG_ 1080 EDS_12VUnderVoltageAlarm_FWD "12V Power under voltage alarm";
CM_ SG_ 1080 EDS_MotOverAlarm_FWD "Motor overspeed fault alarm";
CM_ SG_ 1080 EDS_MotOverFault_FWD "Motor overspeed fault fault";
CM_ SG_ 1080 EDS_iDcLnkOvCLimFail_FWD "Bus current over-current fault";
CM_ SG_ 1080 EDS_MotBlockedFault_FWD "Motor blocked fault";
CM_ SG_ 1080 EDS_RSLErr_FWD "Rotary transformer signal fault";
CM_ SG_ 1080 EDS_MotTrqLimFault_FWD "Motor torque limit fault";
CM_ SG_ 1080 EDS_ResolverOffsetAngle_FWD "EDS offset angle check fault";
CM_ SG_ 1080 EDS_EDSDisChgFault_FWD "EDS Active discharge fault";
CM_ SG_ 1080 EDS_IGBTFault_FWD "IGBT fault";
CM_ SG_ 1080 EDS_CANBusoffFault_FWD "CAN busoff fault";
CM_ SG_ 1080 EDS_TDrvBoardOvHiWarn_FWD "Alarm when drive plate temperature is too high";
CM_ SG_ 1080 EDS_TIGBTOvHiFault_FWD "IGBT junction temperature over temperature fault";
CM_ SG_ 1080 EDS_TIGBTOvHiWarn_FWD "IGBT junction temperature over temperature alarm";
CM_ SG_ 1080 EDS_IOHWABSampFail_FWD "Chip control power sampling failure";
CM_ SG_ 1080 EDS_EDSOpenFault_FWD "EDS open plate fault";
CM_ SG_ 1080 EDS_MotorOpenFault_FWD "Motor open plate fault";
CM_ SG_ 1080 EDS_EmacBlkdWarn_FWD "Motor locked rotor warning";
CM_ SG_ 1080 EDS_VerMatchFailureErr_FWD "EDS Software Version match Failure Fault";
CM_ SG_ 1080 EDS_DiashCirNoPsblErr_FWD "Unable to active short circuit fault";
CM_ SG_ 1080 EDS_OperOutdRngErr_FWD "Short circuit over temperature operation diagnosis";
CM_ SG_ 1080 EDS_PhaseLossFaultErr_FWD "Missing phase fault";
CM_ SG_ 1080 EDS_CPLDFault_FWD "CPLD Fault";
CM_ SG_ 1080 EDS_CPLDFaultBaseSpd_FWD "CPLD enter ASC fault based on motor speed";
CM_ SG_ 1080 EDS_IOHWABNen33Fail_FWD "Feedback NEN33 fault";
CM_ SG_ 1080 EDS_HvMcuSlightFault_RWD "HvMcu Slight fault";
CM_ SG_ 1080 EDS_HvMcuSevFault_FWD "HvMcu serious fault";
CM_ SG_ 1080 EDS_EDSPhaSampHWFault_FWD "UVW phase current monitoring sampling hard wire fault";
CM_ SG_ 1080 EDS_IsOvHiErr_FWD "Phase current overcurrent diagnosis";
CM_ SG_ 1080 EDS_CanRollingCounterErr_FWD "Receive count error";
CM_ SG_ 1080 EDS_CanTimeoutErr_FWD "Receive timeout error";
CM_ SG_ 1080 EDS_CrashFault_FWD "Crash signal fault";
CM_ SG_ 553 Checksum_0x229 "Checksum";
CM_ SG_ 553 Rolling_Counter_0x229 "Rolling counter";
CM_ SG_ 553 VCU_EDS_TargetTqMin_FWD "Min Target torque";
CM_ SG_ 553 VCU_EDS_StsModeReq_FWD "MCU Status Request";
CM_ SG_ 553 VCU_EDS_demtrq_FWD "Driving Requirements Torque from VCU to EDS";
CM_ SG_ 553 VCU_EDS_demtrqValid_FWD "Driving Requirements Torque from VCU to EDS";
CM_ SG_ 553 VCU_EDS_TargetTqMax_FWD "Max Target torque";
CM_ SG_ 553 VCU_EDS_CreepFlg_FWD "Enable  or Disable  Front-Wheel Drive Creep Function";
CM_ SG_ 553 VCU_EDS_HILLHoldFlg_FWD "Enable  or Disable  Front-Wheel Drive HILL Hold Calibration";
CM_ SG_ 937 VCU_PTC_RelaySts "PTC Relayopen or close state";
CM_ SG_ 937 VCU_EACEnbReq "The command of compressor,AC enable signal";
CM_ SG_ 937 VCU_EACAllowedPower "EAC Allowed Power";
CM_ SG_ 937 VCU_EAC_CompSpdReq "Compressor Speed Request";
CM_ SG_ 937 VCU_DriveCoolWaterFlowRate "Actual drive cool water flow rate";
CM_ SG_ 937 VCU_DriveCoolInletWaterTemp "The temperature of inlet radiator";
CM_ SG_ 524 Checksum_0x20C "Checksum";
CM_ SG_ 524 Rolling_Counter_0x20C "Rolling_Counter";
CM_ SG_ 524 IPC_ODO "odograph";
CM_ SG_ 703 IPC_TripA "Set Trip A";
CM_ SG_ 703 IPC_AverageSpeedTripA "Average Speed of TripA";
CM_ SG_ 703 IPC_AverageConsumptionTripA "Average Consumption of TripA";
CM_ SG_ 703 IPC_ParkBrakeSts "Park Brake Status";
CM_ SG_ 703 IPC_VehSpd "Current Displayed Longitudinal Vehicle Speed";
CM_ SG_ 1087 IPC_Sec "Represents the current second.60 - 63 = Invalid";
CM_ SG_ 1087 IPC_Min "Represents the current minute. 60 - 63 = Invalid";
CM_ SG_ 1087 IPC_Hour "Represents the current hour, 24 - 30 = not used";
CM_ SG_ 1087 IPC_Day "Represents the current dayInvalid value = 0";
CM_ SG_ 1087 IPC_Month "Represents the current month.0, 13 to 15 = Invalid";
CM_ SG_ 1087 IPC_Year "Represents the current year.";
CM_ SG_ 1087 IPC_SelfCheckStatus "Power on self check status";
CM_ SG_ 1074 Checksum_0x432 "Checksum";
CM_ SG_ 1074 Rolling_Counter_0x432 "Rolling_Counter";
CM_ SG_ 1074 MHU_FOTA_State "FOTA global status";
CM_ SG_ 1074 MHU_FOTA_Error_Code "FOTA Error Code";
CM_ SG_ 811 CCU_TemperatureGearSts "Temperature Gear Status";
CM_ SG_ 811 CCU_BlowMode_Sts "Blow Mode_Status";
CM_ SG_ 811 CCU_Circulation_Sts "CCU intake cycle state";
CM_ SG_ 811 CCU_AC_Req "Compressor request switch signal";
CM_ SG_ 811 CCU_AC_Sts "AC Status";
CM_ SG_ 811 CCU_BlowerLevelSts "Blower_Level";
CM_ SG_ 811 CCU_FrontDefrostSts "Defrost_Status";
CM_ SG_ 811 CCU_PTC_Req "CCU request VCU to enable or disable PTC";
CM_ SG_ 811 CCU_PTC_Temperature "PTC Temperature";
CM_ SG_ 811 CCU_CompSpdMEAS_Comp "Compressor speed signal";
CM_ SG_ 811 CCU_PollutionSts "Pollution mode state";
CM_ SG_ 811 CCU_ExternalTemperature "External Temperature";
CM_ SG_ 811 CCU_evaporator_Temperature "evaporator Temperature";
CM_ SG_ 811 CCU_ExternalTemperatureFailSts "External Temperature Fail Sts";
CM_ SG_ 274 Checksum_0x112 "Checksum";
CM_ SG_ 274 Rolling_Counter_0x112 "Rolling_Counter";
CM_ SG_ 274 STAT_Terminal "Represent the status of physical terminal(STAT_Terminal to be received by all modules,Required for DTC snapshots and for FOTA)";
CM_ SG_ 274 STAT_CL30s_L_Reserved "Status Clamp 30s Logical ON/OFF";
CM_ SG_ 266 Checksum_0x10a "Checksum";
CM_ SG_ 266 Rolling_Counter_0x10a "Rolling_Counter";
CM_ SG_ 266 BCM_LVTop_up "LV  battery top up requice signal";
CM_ SG_ 266 Ubatt_Reserved "Battery Voltage(UBatt to be received by all modules,Required for DTC snapshots)";
CM_ SG_ 133 Checksum_0x85 "Checksum";
CM_ SG_ 133 Rolling_Counter_0x85 "Rolling Counter";
CM_ SG_ 133 ACM_Crash_Sts "Crash status";
CM_ SG_ 133 ACM_Airbag_Deployment_Status "Signal to indicate if airbag/pretensioner/pyrofuse is deployed";
CM_ SG_ 133 ACM_Crash_Intensity "Indicate crash intensity level";
CM_ SG_ 133 ACM_Front_Crash "Output information for direction of crash";
CM_ SG_ 133 ACM_DriverSide_Crash "Output information for direction of crash";
CM_ SG_ 133 ACM_PassSide_Crash "Output information for direction of crash";
CM_ SG_ 133 ACM_Rear_Crash "Output information for direction of crash";
CM_ SG_ 133 ACM_Rollover_Crash "Output information for direction of crash";
CM_ SG_ 834 Checksum_0x342 "Check sum";
CM_ SG_ 834 Rolling_Counter_0x342 "Rolling Counter";
CM_ SG_ 834 ABS_LRWhlSpdRaw "Current Raw wheel speed information of rear left wheel.";
CM_ SG_ 834 ABS_LRWhlSpdRawValid "Current Raw wheel speed information valid flag of rear left wheel.";
CM_ SG_ 834 ABS_RRWhlSpdRaw "Current Raw wheel speed information of rear right wheel.,";
CM_ SG_ 834 ABS_RRWhlSpdRawValid "Current Raw wheel speed information valid flag of rear right wheel";
CM_ SG_ 834 ABS_VehSpd "Current Longitudinal Vehicle Speed";
CM_ SG_ 834 ABS_VehSpdValid "Speed Valid Flag";
CM_ SG_ 149 Checksum_0x95 "Checksum";
CM_ SG_ 149 RollingCounter_0x95 "Alive counter";
CM_ SG_ 149 ABS_Active "ABS function active.";
CM_ SG_ 149 ASR_Active "ASR Traction Control active";
CM_ SG_ 1299 BMS_sourceID "source ID";
CM_ SG_ 1299 BMS_CBV "CBV";
CM_ SG_ 1299 BMS_Data0 "Data0";
CM_ SG_ 1299 BMS_Data1 "Data1";
CM_ SG_ 1299 BMS_Data2 "Data2";
CM_ SG_ 1299 BMS_Data3 "Data3";
CM_ SG_ 1299 BMS_Data4 "Data4";
CM_ SG_ 1299 BMS_Data5 "Data5";
CM_ SG_ 1324 VCU_sourceID "source ID";
CM_ SG_ 1324 VCU_CBV "CBV";
CM_ SG_ 1324 VCU_Data0 "Data0";
CM_ SG_ 1324 VCU_Data1 "Data1";
CM_ SG_ 1324 VCU_Data2 "Data2";
CM_ SG_ 1324 VCU_Data3 "Data3";
CM_ SG_ 1324 VCU_Data4 "Data4";
CM_ SG_ 1324 VCU_Data5 "Data5";
CM_ SG_ 1341 PDU_DCDC_sourceID "source ID";
CM_ SG_ 1341 PDU_DCDC_CBV "CBV";
CM_ SG_ 1341 PDU_DCDC_Data0 "Data0";
CM_ SG_ 1341 PDU_DCDC_Data1 "Data1";
CM_ SG_ 1341 PDU_DCDC_Data2 "Data2";
CM_ SG_ 1341 PDU_DCDC_Data3 "Data3";
CM_ SG_ 1341 PDU_DCDC_Data4 "Data4";
CM_ SG_ 1341 PDU_DCDC_Data5 "Data5";
CM_ SG_ 1307 EDS_sourceID "source ID";
CM_ SG_ 1307 EDS_CBV "CBV";
CM_ SG_ 1307 EDS_Data0 "Data0";
CM_ SG_ 1307 EDS_Data1 "Data1";
CM_ SG_ 1307 EDS_Data2 "Data2";
CM_ SG_ 1307 EDS_Data3 "Data3";
CM_ SG_ 1307 EDS_Data4 "Data4";
CM_ SG_ 1307 EDS_Data5 "Data5";
CM_ SG_ 1311 EVCC_sourceID "source ID";
CM_ SG_ 1311 EVCC_CBV "CBV";
CM_ SG_ 1311 EVCC_Data0 "Data0";
CM_ SG_ 1311 EVCC_Data1 "Data1";
CM_ SG_ 1311 EVCC_Data2 "Data2";
CM_ SG_ 1311 EVCC_Data3 "Data3";
CM_ SG_ 1311 EVCC_Data4 "Data4";
CM_ SG_ 1311 EVCC_Data5 "Data5";
CM_ SG_ 1282 GW_sourceID "source ID";
CM_ SG_ 1282 GW_CBV "CBV";
CM_ SG_ 1282 GW_Data0 "Data0";
CM_ SG_ 1282 GW_Data1 "Data1";
CM_ SG_ 1282 GW_Data2 "Data2";
CM_ SG_ 1282 GW_Data3 "Data3";
CM_ SG_ 1282 GW_Data4 "Data4";
CM_ SG_ 1282 GW_Data5 "Data5";
CM_ SG_ 1691 EDS_DiagReqData0 "Data0";
CM_ SG_ 1691 EDS_DiagReqData1 "Data1";
CM_ SG_ 1691 EDS_DiagReqData2 "Data2";
CM_ SG_ 1691 EDS_DiagReqData3 "Data3";
CM_ SG_ 1691 EDS_DiagReqData4 "Data4";
CM_ SG_ 1691 EDS_DiagReqData5 "Data5";
CM_ SG_ 1691 EDS_DiagReqData6 "Data6";
CM_ SG_ 1691 EDS_DiagReqData7 "Data7";
CM_ SG_ 1563 EDS_DiagRespData0 "Data0";
CM_ SG_ 1563 EDS_DiagRespData1 "Data1";
CM_ SG_ 1563 EDS_DiagRespData2 "Data2";
CM_ SG_ 1563 EDS_DiagRespData3 "Data3";
CM_ SG_ 1563 EDS_DiagRespData4 "Data4";
CM_ SG_ 1563 EDS_DiagRespData5 "Data5";
CM_ SG_ 1563 EDS_DiagRespData6 "Data6";
CM_ SG_ 1563 EDS_DiagRespData7 "Data7";
CM_ SG_ 1791 GW_DiagFunctionalAddressingData0 "Data0";
CM_ SG_ 1791 GW_DiagFunctionalAddressingData1 "Data1";
CM_ SG_ 1791 GW_DiagFunctionalAddressingData2 "Data2";
CM_ SG_ 1791 GW_DiagFunctionalAddressingData3 "Data3";
CM_ SG_ 1791 GW_DiagFunctionalAddressingData4 "Data4";
CM_ SG_ 1791 GW_DiagFunctionalAddressingData5 "Data5";
CM_ SG_ 1791 GW_DiagFunctionalAddressingData6 "Data6";
CM_ SG_ 1791 GW_DiagFunctionalAddressingData7 "Data7";
BA_DEF_ BO_ "DiagRequest" ENUM "No","Yes";
BA_DEF_ BO_ "DiagResponse" ENUM "No","Yes";
BA_DEF_ BO_ "DiagState" ENUM "No","Yes";
BA_DEF_ BO_ "GenMsgCycleTime" INT 0 65535;
BA_DEF_ BO_ "GenMsgCycleTimeFast" INT 0 65535;
BA_DEF_ BO_ "GenMsgDelayTime" INT 0 65535;
BA_DEF_ BO_ "GenMsgILSupport" ENUM "No","Yes";
BA_DEF_ BO_ "GenMsgNrOfRepetition" INT 0 65535;
BA_DEF_ BO_ "GenMsgSendType" ENUM  "Cycle","Event","IfActive","CE","CA";
BA_DEF_ BO_ "NmAsrMessage" ENUM "No","Yes";
BA_DEF_ BO_ "NmMessage" ENUM "No","Yes";
BA_DEF_ SG_ "GenSigSendType" ENUM  "Cycle","OnWrite","OnWriteWithRepetition","OnChange","OnChangeWithRepetition","IfActive","IfActiveWithRepetition";
BA_DEF_ SG_ "GenSigStartValue" INT 0 2147483647;
BA_DEF_ SG_ "GenSigInvalidValue" INT 0 2147483647;
BA_DEF_ SG_ "GenSigInactiveValue" INT 0 2147483647;
BA_DEF_ BU_ "ILUsed" ENUM  "No","Yes";
BA_DEF_ BU_ "NmAsrCanMsgReducedTime" INT 320 640;
BA_DEF_ BU_ "NmAsrNode" ENUM  "No","Yes";
BA_DEF_  "Baudrate" INT 0 1000000;
BA_DEF_  "BusType" STRING;
BA_DEF_  "Manufacturer" STRING;
BA_DEF_  "NmAsrBaseAddress" HEX 0 2047;
BA_DEF_  "NmAsrCanMsgCycleTime" INT 0 65535;
BA_DEF_  "NmAsrMessageCount" INT 1 256;
BA_DEF_  "NmAsrRepeatMessageTime" INT 0 65535;
BA_DEF_  "NmAsrTimeoutTime" INT 0 65535;
BA_DEF_  "NmAsrWaitBusSleepTime" INT 0 65535;
BA_DEF_  "NmType" STRING;
BA_DEF_DEF_ "Baudrate" 500000;
BA_DEF_DEF_ "BusType" "CAN";
BA_DEF_DEF_ "DiagRequest" "No";
BA_DEF_DEF_ "DiagResponse" "No";
BA_DEF_DEF_ "DiagState" "No";
BA_DEF_DEF_ "GenMsgCycleTime" 0;
BA_DEF_DEF_ "GenMsgCycleTimeFast" 0;
BA_DEF_DEF_ "GenMsgDelayTime" 0;
BA_DEF_DEF_ "GenMsgILSupport" "Yes";
BA_DEF_DEF_ "GenMsgNrOfRepetition" 0;
BA_DEF_DEF_ "GenMsgSendType" "NoMsgSendType";
BA_DEF_DEF_ "GenSigSendType" "NoSigSendType";
BA_DEF_DEF_ "GenSigStartValue" 0;
BA_DEF_DEF_  "GenSigInvalidValue" 0;
BA_DEF_DEF_ "GenSigInactiveValue" 0;
BA_DEF_DEF_ "ILUsed" "Yes";
BA_DEF_DEF_ "Manufacturer" "Launch";
BA_DEF_DEF_ "NmAsrBaseAddress" 1280;
BA_DEF_DEF_ "NmAsrCanMsgCycleTime" 640;
BA_DEF_DEF_ "NmAsrCanMsgReducedTime" 320;
BA_DEF_DEF_ "NmAsrMessage" "No";
BA_DEF_DEF_ "NmAsrMessageCount" 128;
BA_DEF_DEF_ "NmAsrNode" "No";
BA_DEF_DEF_ "NmAsrRepeatMessageTime" 3200;
BA_DEF_DEF_ "NmAsrTimeoutTime" 2000;
BA_DEF_DEF_ "NmAsrWaitBusSleepTime" 1500;
BA_DEF_DEF_ "NmMessage" "No";
BA_DEF_DEF_ "NmType" "NmAsr";

BA_ "NmAsrNode" BU_ EDS_F 1;
BA_ "GenMsgSendType" BO_ 374 0;
BA_ "GenMsgCycleTime" BO_ 374 50;
BA_ "GenMsgSendType" BO_ 533 0;
BA_ "GenMsgCycleTime" BO_ 533 50;
BA_ "GenMsgSendType" BO_ 885 0;
BA_ "GenMsgCycleTime" BO_ 885 50;
BA_ "GenMsgSendType" BO_ 840 0;
BA_ "GenMsgCycleTime" BO_ 840 50;
BA_ "GenMsgSendType" BO_ 504 0;
BA_ "GenMsgCycleTime" BO_ 504 10;
BA_ "GenMsgSendType" BO_ 680 0;
BA_ "GenMsgCycleTime" BO_ 680 20;
BA_ "GenMsgSendType" BO_ 568 0;
BA_ "GenMsgCycleTime" BO_ 568 20;
BA_ "GenMsgSendType" BO_ 1080 0;
BA_ "GenMsgCycleTime" BO_ 1080 100;
BA_ "GenMsgSendType" BO_ 553 0;
BA_ "GenMsgCycleTime" BO_ 553 10;
BA_ "GenMsgSendType" BO_ 937 0;
BA_ "GenMsgCycleTime" BO_ 937 20;
BA_ "GenMsgSendType" BO_ 524 0;
BA_ "GenMsgCycleTime" BO_ 524 100;
BA_ "GenMsgSendType" BO_ 703 0;
BA_ "GenMsgCycleTime" BO_ 703 50;
BA_ "GenMsgSendType" BO_ 1087 0;
BA_ "GenMsgCycleTime" BO_ 1087 1000;
BA_ "GenMsgSendType" BO_ 1074 0;
BA_ "GenMsgDelayTime" BO_ 1074 50;
BA_ "GenMsgCycleTime" BO_ 1074 100;
BA_ "GenMsgSendType" BO_ 811 0;
BA_ "GenMsgCycleTime" BO_ 811 50;
BA_ "GenMsgSendType" BO_ 274 0;
BA_ "GenMsgCycleTime" BO_ 274 100;
BA_ "GenMsgSendType" BO_ 266 0;
BA_ "GenMsgCycleTime" BO_ 266 100;
BA_ "GenMsgSendType" BO_ 133 0;
BA_ "GenMsgCycleTime" BO_ 133 20;
BA_ "GenMsgSendType" BO_ 834 0;
BA_ "GenMsgCycleTime" BO_ 834 10;
BA_ "GenMsgSendType" BO_ 149 0;
BA_ "GenMsgCycleTime" BO_ 149 100;
BA_ "GenMsgSendType" BO_ 1299 2;
BA_ "GenMsgCycleTime" BO_ 1299 640;
BA_ "NmAsrMessage" BO_ 1299 1;
BA_ "NmMessage" BO_ 1299 1;
BA_ "GenMsgSendType" BO_ 1324 2;
BA_ "GenMsgCycleTime" BO_ 1324 640;
BA_ "NmAsrMessage" BO_ 1324 1;
BA_ "NmMessage" BO_ 1324 1;
BA_ "GenMsgSendType" BO_ 1341 2;
BA_ "GenMsgCycleTime" BO_ 1341 640;
BA_ "NmAsrMessage" BO_ 1341 1;
BA_ "NmMessage" BO_ 1341 1;
BA_ "GenMsgSendType" BO_ 1307 2;
BA_ "GenMsgCycleTime" BO_ 1307 640;
BA_ "NmAsrMessage" BO_ 1307 1;
BA_ "NmMessage" BO_ 1307 1;
BA_ "GenMsgSendType" BO_ 1311 2;
BA_ "GenMsgCycleTime" BO_ 1311 640;
BA_ "NmAsrMessage" BO_ 1311 1;
BA_ "NmMessage" BO_ 1311 1;
BA_ "GenMsgSendType" BO_ 1282 2;
BA_ "GenMsgCycleTime" BO_ 1282 640;
BA_ "NmAsrMessage" BO_ 1282 1;
BA_ "NmMessage" BO_ 1282 1;
BA_ "GenMsgSendType" BO_ 1691 1;
BA_ "DiagRequest" BO_ 1691 1;
BA_ "GenMsgSendType" BO_ 1563 1;
BA_ "DiagResponse" BO_ 1563 1;
BA_ "GenMsgSendType" BO_ 1791 1;
BA_ "DiagState" BO_ 1791 1;
BA_ "GenSigSendType" SG_ 374 Checksum_0x176 0;
BA_ "GenSigSendType" SG_ 374 Rolling_Counter_0x176 0;
BA_ "GenSigInvalidValue" SG_ 374 Rolling_Counter_0x176 15;
BA_ "GenSigSendType" SG_ 374 BMS_HVLinkVol_MEAS 0;
BA_ "GenSigInvalidValue" SG_ 374 BMS_HVLinkVol_MEAS 65535;
BA_ "GenSigSendType" SG_ 374 BMS_HVPackVol_MEAS 0;
BA_ "GenSigInvalidValue" SG_ 374 BMS_HVPackVol_MEAS 65535;
BA_ "GenSigSendType" SG_ 533 Checksum_0x215 0;
BA_ "GenSigSendType" SG_ 533 Rolling_Counter_0x215 0;
BA_ "GenSigInvalidValue" SG_ 533 Rolling_Counter_0x215 15;
BA_ "GenSigSendType" SG_ 533 BMS_SOE 0;
BA_ "GenSigStartValue" SG_ 533 BMS_SOE 54;
BA_ "GenSigSendType" SG_ 533 BMS_HWCrash_Sts 0;
BA_ "GenSigSendType" SG_ 533 BMS_HVIL_STS 0;
BA_ "GenSigSendType" SG_ 533 BMS_IGN_Sts 0;
BA_ "GenSigSendType" SG_ 533 BMS_Sys_STS 0;
BA_ "GenSigSendType" SG_ 533 BMS_HVOnOff_STS 0;
BA_ "GenSigSendType" SG_ 533 BMS_Balance_STS 0;
BA_ "GenSigSendType" SG_ 533 BMS_SocActual_EST 0;
BA_ "GenSigSendType" SG_ 533 BMS_BatBalance_ERR 0;
BA_ "GenSigSendType" SG_ 533 BMS_ISU_Status 0;
BA_ "GenSigSendType" SG_ 533 BMS_ERR_LEV 0;
BA_ "GenSigSendType" SG_ 533 BMS_SOH 0;
BA_ "GenSigStartValue" SG_ 533 BMS_SOH 54;
BA_ "GenSigSendType" SG_ 533 BMS_HV_Sts 0;
BA_ "GenSigSendType" SG_ 885 Checksum_0x375 0;
BA_ "GenSigSendType" SG_ 885 Rolling_Counter_0x375 0;
BA_ "GenSigInvalidValue" SG_ 885 Rolling_Counter_0x375 15;
BA_ "GenSigSendType" SG_ 885 BMS_MainPosRelay_ERR 0;
BA_ "GenSigSendType" SG_ 885 BMS_MainPosRelay_STS 0;
BA_ "GenSigInvalidValue" SG_ 885 BMS_MainPosRelay_STS 7;
BA_ "GenSigSendType" SG_ 885 BMS_PreChgRelay_ERR 0;
BA_ "GenSigSendType" SG_ 885 BMS_PreChgRelay_STS 0;
BA_ "GenSigInvalidValue" SG_ 885 BMS_PreChgRelay_STS 7;
BA_ "GenSigSendType" SG_ 885 BMS_TotalNegRelay_STS 0;
BA_ "GenSigInvalidValue" SG_ 885 BMS_TotalNegRelay_STS 7;
BA_ "GenSigSendType" SG_ 885 BMS_TotalNegRelay_ERR 0;
BA_ "GenSigSendType" SG_ 840 EDS_bus_Volt_FWD 0;
BA_ "GenSigInvalidValue" SG_ 840 EDS_bus_Volt_FWD 16383;
BA_ "GenSigSendType" SG_ 840 EDS_bus_Curr_FWD 0;
BA_ "GenSigInvalidValue" SG_ 840 EDS_bus_Curr_FWD 65535;
BA_ "GenSigStartValue" SG_ 840 EDS_bus_Curr_FWD 10000;
BA_ "GenSigSendType" SG_ 840 EDS_MtrNumb_FWD 0;
BA_ "GenSigSendType" SG_ 840 EDS_DriveMtrNmb_FWD 0;
BA_ "GenSigSendType" SG_ 840 EDS_HVIL_STS_FWD 0;
BA_ "GenSigSendType" SG_ 504 Checksum_0x1F8 0;
BA_ "GenSigSendType" SG_ 504 Rolling_Counter_0x1F8 0;
BA_ "GenSigInvalidValue" SG_ 504 Rolling_Counter_0x1F8 15;
BA_ "GenSigSendType" SG_ 504 EDS_output_trq_FR 0;
BA_ "GenSigInvalidValue" SG_ 504 EDS_output_trq_FR 65535;
BA_ "GenSigStartValue" SG_ 504 EDS_output_trq_FR 2000;
BA_ "GenSigSendType" SG_ 504 EDS_output_trqValid_FR 0;
BA_ "GenSigSendType" SG_ 504 EDS_Spd_FR 0;
BA_ "GenSigInvalidValue" SG_ 504 EDS_Spd_FR 65535;
BA_ "GenSigStartValue" SG_ 504 EDS_Spd_FR 20000;
BA_ "GenSigSendType" SG_ 504 EDS_SpdValid_FR 0;
BA_ "GenSigSendType" SG_ 504 EDS_MotorDriveSts_FR 0;
BA_ "GenSigInvalidValue" SG_ 504 EDS_MotorDriveSts_FR 3;
BA_ "GenSigSendType" SG_ 504 EDS_Work_STS_FR 0;
BA_ "GenSigInvalidValue" SG_ 504 EDS_Work_STS_FR 15;
BA_ "GenSigSendType" SG_ 504 EDS_powoff_req_FR 0;
BA_ "GenSigSendType" SG_ 680 Checksum_0x2A8 0;
BA_ "GenSigSendType" SG_ 680 Rolling_Counter_0x2A8 0;
BA_ "GenSigInvalidValue" SG_ 680 Rolling_Counter_0x2A8 15;
BA_ "GenSigSendType" SG_ 680 EDS_MotorSerialNum_FWD 0;
BA_ "GenSigStartValue" SG_ 680 EDS_MotorSerialNum_FWD 1;
BA_ "GenSigSendType" SG_ 680 EDS_MinTrq_FWD 0;
BA_ "GenSigInvalidValue" SG_ 680 EDS_MinTrq_FWD 65535;
BA_ "GenSigStartValue" SG_ 680 EDS_MinTrq_FWD 4000;
BA_ "GenSigSendType" SG_ 680 EDS_MaxTrq_FWD 0;
BA_ "GenSigInvalidValue" SG_ 680 EDS_MaxTrq_FWD 65535;
BA_ "GenSigStartValue" SG_ 680 EDS_MaxTrq_FWD 4000;
BA_ "GenSigSendType" SG_ 568 EDS_MotTemp_MEAS_EDS_FWD 0;
BA_ "GenSigInvalidValue" SG_ 568 EDS_MotTemp_MEAS_EDS_FWD 255;
BA_ "GenSigStartValue" SG_ 568 EDS_MotTemp_MEAS_EDS_FWD 80;
BA_ "GenSigSendType" SG_ 568 EDS_MotTemp_MEAS_EDS_valid_FWD 0;
BA_ "GenSigSendType" SG_ 568 EDS_temp_FWD 0;
BA_ "GenSigInvalidValue" SG_ 568 EDS_temp_FWD 255;
BA_ "GenSigStartValue" SG_ 568 EDS_temp_FWD 80;
BA_ "GenSigSendType" SG_ 568 EDS_tempValid_FWD 0;
BA_ "GenSigSendType" SG_ 568 EDS_disxhg_st_FWD 0;
BA_ "GenSigSendType" SG_ 568 EDS_IGBTState_FWD 0;
BA_ "GenSigSendType" SG_ 568 EDS_DampingState_FWD 0;
BA_ "GenSigSendType" SG_ 568 EDS_CoolFlowrate_DMD_FWD 0;
BA_ "GenSigInvalidValue" SG_ 568 EDS_CoolFlowrate_DMD_FWD 255;
BA_ "GenSigSendType" SG_ 1080 EDS_FailNum_ERR_FWD 0;
BA_ "GenSigSendType" SG_ 1080 EDS_FailGrade_ERR_FWD 0;
BA_ "GenSigSendType" SG_ 1080 EDS_MotOverTempAlarm_FWD 0;
BA_ "GenSigSendType" SG_ 1080 EDS_MotOverTempFault_FWD 0;
BA_ "GenSigSendType" SG_ 1080 EDS_MotTempSenFault_FWD 0;
BA_ "GenSigSendType" SG_ 1080 EDS_EDSOverTempUFault_FWD 0;
BA_ "GenSigSendType" SG_ 1080 EDS_EDSOverTempVFault_FWD 0;
BA_ "GenSigSendType" SG_ 1080 EDS_EDSOverTempWFault_FWD 0;
BA_ "GenSigSendType" SG_ 1080 EDS_EDSOverTempAlarm_FWD 0;
BA_ "GenSigSendType" SG_ 1080 EDS_TCoolantOvHi_FWD 0;
BA_ "GenSigSendType" SG_ 1080 EDS_EDSTempCmpAlarm_FWD 0;
BA_ "GenSigSendType" SG_ 1080 EDS_EDSPhaOvCurentHWFault_FWD 0;
BA_ "GenSigSendType" SG_ 1080 EDS_EDSphaOffCalFault_FWD 0;
BA_ "GenSigSendType" SG_ 1080 EDS_EDSOverIdcLnkAlarm_FWD 0;
BA_ "GenSigSendType" SG_ 1080 EDS_EDSHVOverVoltageAlarm_FWD 0;
BA_ "GenSigSendType" SG_ 1080 EDS_EDSHVOverVoltageFault_FWD 0;
BA_ "GenSigSendType" SG_ 1080 EDS_EDSHVUnderVoltageAlarm_FWD 0;
BA_ "GenSigSendType" SG_ 1080 EDS_EDSHVUnderVoltageFault_FWD 0;
BA_ "GenSigSendType" SG_ 1080 EDS_RunToDischaErr_FWD 0;
BA_ "GenSigSendType" SG_ 1080 EDS_12VOverVoltageAlarm_FWD 0;
BA_ "GenSigSendType" SG_ 1080 EDS_12VUnderVoltageAlarm_FWD 0;
BA_ "GenSigSendType" SG_ 1080 EDS_MotOverAlarm_FWD 0;
BA_ "GenSigSendType" SG_ 1080 EDS_MotOverFault_FWD 0;
BA_ "GenSigSendType" SG_ 1080 EDS_iDcLnkOvCLimFail_FWD 0;
BA_ "GenSigSendType" SG_ 1080 EDS_MotBlockedFault_FWD 0;
BA_ "GenSigSendType" SG_ 1080 EDS_RSLErr_FWD 0;
BA_ "GenSigSendType" SG_ 1080 EDS_MotTrqLimFault_FWD 0;
BA_ "GenSigSendType" SG_ 1080 EDS_ResolverOffsetAngle_FWD 0;
BA_ "GenSigSendType" SG_ 1080 EDS_EDSDisChgFault_FWD 0;
BA_ "GenSigSendType" SG_ 1080 EDS_IGBTFault_FWD 0;
BA_ "GenSigSendType" SG_ 1080 EDS_CANBusoffFault_FWD 0;
BA_ "GenSigSendType" SG_ 1080 EDS_TDrvBoardOvHiWarn_FWD 0;
BA_ "GenSigSendType" SG_ 1080 EDS_TIGBTOvHiFault_FWD 0;
BA_ "GenSigSendType" SG_ 1080 EDS_TIGBTOvHiWarn_FWD 0;
BA_ "GenSigSendType" SG_ 1080 EDS_IOHWABSampFail_FWD 0;
BA_ "GenSigSendType" SG_ 1080 EDS_EDSOpenFault_FWD 0;
BA_ "GenSigSendType" SG_ 1080 EDS_MotorOpenFault_FWD 0;
BA_ "GenSigSendType" SG_ 1080 EDS_EmacBlkdWarn_FWD 0;
BA_ "GenSigSendType" SG_ 1080 EDS_VerMatchFailureErr_FWD 0;
BA_ "GenSigSendType" SG_ 1080 EDS_DiashCirNoPsblErr_FWD 0;
BA_ "GenSigSendType" SG_ 1080 EDS_OperOutdRngErr_FWD 0;
BA_ "GenSigSendType" SG_ 1080 EDS_PhaseLossFaultErr_FWD 0;
BA_ "GenSigSendType" SG_ 1080 EDS_CPLDFault_FWD 0;
BA_ "GenSigSendType" SG_ 1080 EDS_CPLDFaultBaseSpd_FWD 0;
BA_ "GenSigSendType" SG_ 1080 EDS_IOHWABNen33Fail_FWD 0;
BA_ "GenSigSendType" SG_ 1080 EDS_HvMcuSlightFault_RWD 0;
BA_ "GenSigSendType" SG_ 1080 EDS_HvMcuSevFault_FWD 0;
BA_ "GenSigSendType" SG_ 1080 EDS_EDSPhaSampHWFault_FWD 0;
BA_ "GenSigSendType" SG_ 1080 EDS_IsOvHiErr_FWD 0;
BA_ "GenSigSendType" SG_ 1080 EDS_CanRollingCounterErr_FWD 0;
BA_ "GenSigSendType" SG_ 1080 EDS_CanTimeoutErr_FWD 0;
BA_ "GenSigSendType" SG_ 1080 EDS_CrashFault_FWD 0;
BA_ "GenSigSendType" SG_ 553 Checksum_0x229 0;
BA_ "GenSigSendType" SG_ 553 Rolling_Counter_0x229 0;
BA_ "GenSigInvalidValue" SG_ 553 Rolling_Counter_0x229 15;
BA_ "GenSigSendType" SG_ 553 VCU_EDS_TargetTqMin_FWD 0;
BA_ "GenSigInvalidValue" SG_ 553 VCU_EDS_TargetTqMin_FWD 1023;
BA_ "GenSigStartValue" SG_ 553 VCU_EDS_TargetTqMin_FWD 500;
BA_ "GenSigSendType" SG_ 553 VCU_EDS_StsModeReq_FWD 0;
BA_ "GenSigInvalidValue" SG_ 553 VCU_EDS_StsModeReq_FWD 15;
BA_ "GenSigSendType" SG_ 553 VCU_EDS_demtrq_FWD 0;
BA_ "GenSigInvalidValue" SG_ 553 VCU_EDS_demtrq_FWD 4095;
BA_ "GenSigStartValue" SG_ 553 VCU_EDS_demtrq_FWD 1000;
BA_ "GenSigSendType" SG_ 553 VCU_EDS_demtrqValid_FWD 0;
BA_ "GenSigSendType" SG_ 553 VCU_EDS_TargetTqMax_FWD 0;
BA_ "GenSigInvalidValue" SG_ 553 VCU_EDS_TargetTqMax_FWD 1023;
BA_ "GenSigSendType" SG_ 553 VCU_EDS_CreepFlg_FWD 0;
BA_ "GenSigSendType" SG_ 553 VCU_EDS_HILLHoldFlg_FWD 0;
BA_ "GenSigSendType" SG_ 937 VCU_PTC_RelaySts 0;
BA_ "GenSigSendType" SG_ 937 VCU_EACEnbReq 0;
BA_ "GenSigSendType" SG_ 937 VCU_EACAllowedPower 0;
BA_ "GenSigInvalidValue" SG_ 937 VCU_EACAllowedPower 1023;
BA_ "GenSigSendType" SG_ 937 VCU_EAC_CompSpdReq 0;
BA_ "GenSigInvalidValue" SG_ 937 VCU_EAC_CompSpdReq 16383;
BA_ "GenSigSendType" SG_ 937 VCU_DriveCoolWaterFlowRate 0;
BA_ "GenSigSendType" SG_ 937 VCU_DriveCoolInletWaterTemp 0;
BA_ "GenSigSendType" SG_ 524 Checksum_0x20C 0;
BA_ "GenSigSendType" SG_ 524 Rolling_Counter_0x20C 0;
BA_ "GenSigInvalidValue" SG_ 524 Rolling_Counter_0x20C 15;
BA_ "GenSigSendType" SG_ 524 IPC_ODO 0;
BA_ "GenSigInvalidValue" SG_ 524 IPC_ODO 1048575;
BA_ "GenSigSendType" SG_ 703 IPC_TripA 0;
BA_ "GenSigInvalidValue" SG_ 703 IPC_TripA 65535;
BA_ "GenSigSendType" SG_ 703 IPC_AverageSpeedTripA 0;
BA_ "GenSigInvalidValue" SG_ 703 IPC_AverageSpeedTripA 4095;
BA_ "GenSigSendType" SG_ 703 IPC_AverageConsumptionTripA 0;
BA_ "GenSigInvalidValue" SG_ 703 IPC_AverageConsumptionTripA 1023;
BA_ "GenSigSendType" SG_ 703 IPC_ParkBrakeSts 0;
BA_ "GenSigInvalidValue" SG_ 703 IPC_ParkBrakeSts 3;
BA_ "GenSigSendType" SG_ 703 IPC_VehSpd 0;
BA_ "GenSigInvalidValue" SG_ 703 IPC_VehSpd 32767;
BA_ "GenSigSendType" SG_ 1087 IPC_Sec 0;
BA_ "GenSigInvalidValue" SG_ 1087 IPC_Sec 63;
BA_ "GenSigSendType" SG_ 1087 IPC_Min 0;
BA_ "GenSigInvalidValue" SG_ 1087 IPC_Min 63;
BA_ "GenSigSendType" SG_ 1087 IPC_Hour 0;
BA_ "GenSigInvalidValue" SG_ 1087 IPC_Hour 31;
BA_ "GenSigSendType" SG_ 1087 IPC_Day 0;
BA_ "GenSigInvalidValue" SG_ 1087 IPC_Day 31;
BA_ "GenSigStartValue" SG_ 1087 IPC_Day 1;
BA_ "GenSigSendType" SG_ 1087 IPC_Month 0;
BA_ "GenSigInvalidValue" SG_ 1087 IPC_Month 15;
BA_ "GenSigStartValue" SG_ 1087 IPC_Month 1;
BA_ "GenSigSendType" SG_ 1087 IPC_Year 0;
BA_ "GenSigInvalidValue" SG_ 1087 IPC_Year 255;
BA_ "GenSigSendType" SG_ 1087 IPC_SelfCheckStatus 0;
BA_ "GenSigSendType" SG_ 1074 Checksum_0x432 0;
BA_ "GenSigSendType" SG_ 1074 Rolling_Counter_0x432 0;
BA_ "GenSigInvalidValue" SG_ 1074 Rolling_Counter_0x432 15;
BA_ "GenSigSendType" SG_ 1074 MHU_FOTA_State 0;
BA_ "GenSigSendType" SG_ 1074 MHU_FOTA_Error_Code 0;
BA_ "GenSigSendType" SG_ 811 CCU_TemperatureGearSts 0;
BA_ "GenSigInvalidValue" SG_ 811 CCU_TemperatureGearSts 63;
BA_ "GenSigStartValue" SG_ 811 CCU_TemperatureGearSts 7;
BA_ "GenSigSendType" SG_ 811 CCU_BlowMode_Sts 0;
BA_ "GenSigInvalidValue" SG_ 811 CCU_BlowMode_Sts 7;
BA_ "GenSigStartValue" SG_ 811 CCU_BlowMode_Sts 2;
BA_ "GenSigSendType" SG_ 811 CCU_Circulation_Sts 0;
BA_ "GenSigSendType" SG_ 811 CCU_AC_Req 0;
BA_ "GenSigInvalidValue" SG_ 811 CCU_AC_Req 3;
BA_ "GenSigSendType" SG_ 811 CCU_AC_Sts 0;
BA_ "GenSigSendType" SG_ 811 CCU_BlowerLevelSts 0;
BA_ "GenSigStartValue" SG_ 811 CCU_BlowerLevelSts 1;
BA_ "GenSigSendType" SG_ 811 CCU_FrontDefrostSts 0;
BA_ "GenSigSendType" SG_ 811 CCU_PTC_Req 0;
BA_ "GenSigInvalidValue" SG_ 811 CCU_PTC_Req 3;
BA_ "GenSigSendType" SG_ 811 CCU_PTC_Temperature 0;
BA_ "GenSigInvalidValue" SG_ 811 CCU_PTC_Temperature 1023;
BA_ "GenSigSendType" SG_ 811 CCU_CompSpdMEAS_Comp 0;
BA_ "GenSigInvalidValue" SG_ 811 CCU_CompSpdMEAS_Comp 8191;
BA_ "GenSigSendType" SG_ 811 CCU_PollutionSts 0;
BA_ "GenSigSendType" SG_ 811 CCU_ExternalTemperature 0;
BA_ "GenSigInvalidValue" SG_ 811 CCU_ExternalTemperature 255;
BA_ "GenSigStartValue" SG_ 811 CCU_ExternalTemperature 80;
BA_ "GenSigSendType" SG_ 811 CCU_evaporator_Temperature 0;
BA_ "GenSigInvalidValue" SG_ 811 CCU_evaporator_Temperature 31;
BA_ "GenSigStartValue" SG_ 811 CCU_evaporator_Temperature 10;
BA_ "GenSigSendType" SG_ 811 CCU_ExternalTemperatureFailSts 0;
BA_ "GenSigInvalidValue" SG_ 811 CCU_ExternalTemperatureFailSts 1;
BA_ "GenSigStartValue" SG_ 811 CCU_ExternalTemperatureFailSts 1;
BA_ "GenSigSendType" SG_ 274 Checksum_0x112 0;
BA_ "GenSigSendType" SG_ 274 Rolling_Counter_0x112 0;
BA_ "GenSigInvalidValue" SG_ 274 Rolling_Counter_0x112 15;
BA_ "GenSigSendType" SG_ 274 STAT_Terminal 0;
BA_ "GenSigSendType" SG_ 274 STAT_CL30s_L_Reserved 0;
BA_ "GenSigStartValue" SG_ 274 STAT_CL30s_L_Reserved 3;
BA_ "GenSigSendType" SG_ 266 Checksum_0x10a 0;
BA_ "GenSigSendType" SG_ 266 Rolling_Counter_0x10a 0;
BA_ "GenSigInvalidValue" SG_ 266 Rolling_Counter_0x10a 15;
BA_ "GenSigSendType" SG_ 266 BCM_LVTop_up 0;
BA_ "GenSigSendType" SG_ 266 Ubatt_Reserved 0;
BA_ "GenSigInvalidValue" SG_ 266 Ubatt_Reserved 16383;
BA_ "GenSigStartValue" SG_ 266 Ubatt_Reserved 9000;
BA_ "GenSigSendType" SG_ 133 Checksum_0x85 0;
BA_ "GenSigSendType" SG_ 133 Rolling_Counter_0x85 0;
BA_ "GenSigInvalidValue" SG_ 133 Rolling_Counter_0x85 15;
BA_ "GenSigSendType" SG_ 133 ACM_Crash_Sts 0;
BA_ "GenSigSendType" SG_ 133 ACM_Airbag_Deployment_Status 0;
BA_ "GenSigSendType" SG_ 133 ACM_Crash_Intensity 0;
BA_ "GenSigSendType" SG_ 133 ACM_Front_Crash 0;
BA_ "GenSigSendType" SG_ 133 ACM_DriverSide_Crash 0;
BA_ "GenSigSendType" SG_ 133 ACM_PassSide_Crash 0;
BA_ "GenSigSendType" SG_ 133 ACM_Rear_Crash 0;
BA_ "GenSigSendType" SG_ 133 ACM_Rollover_Crash 0;
BA_ "GenSigSendType" SG_ 834 Checksum_0x342 0;
BA_ "GenSigSendType" SG_ 834 Rolling_Counter_0x342 0;
BA_ "GenSigInvalidValue" SG_ 834 Rolling_Counter_0x342 15;
BA_ "GenSigSendType" SG_ 834 ABS_LRWhlSpdRaw 0;
BA_ "GenSigInvalidValue" SG_ 834 ABS_LRWhlSpdRaw 32767;
BA_ "GenSigSendType" SG_ 834 ABS_LRWhlSpdRawValid 0;
BA_ "GenSigSendType" SG_ 834 ABS_RRWhlSpdRaw 0;
BA_ "GenSigInvalidValue" SG_ 834 ABS_RRWhlSpdRaw 32767;
BA_ "GenSigSendType" SG_ 834 ABS_RRWhlSpdRawValid 0;
BA_ "GenSigSendType" SG_ 834 ABS_VehSpd 0;
BA_ "GenSigInvalidValue" SG_ 834 ABS_VehSpd 32767;
BA_ "GenSigSendType" SG_ 834 ABS_VehSpdValid 0;
BA_ "GenSigSendType" SG_ 149 Checksum_0x95 0;
BA_ "GenSigSendType" SG_ 149 RollingCounter_0x95 0;
BA_ "GenSigInvalidValue" SG_ 149 RollingCounter_0x95 15;
BA_ "GenSigSendType" SG_ 149 ABS_Active 0;
BA_ "GenSigInvalidValue" SG_ 149 ABS_Active 3;
BA_ "GenSigSendType" SG_ 149 ASR_Active 0;
BA_ "GenSigInvalidValue" SG_ 149 ASR_Active 3;
BA_ "GenSigSendType" SG_ 1299 BMS_sourceID 0;
BA_ "GenSigSendType" SG_ 1299 BMS_CBV 0;
BA_ "GenSigSendType" SG_ 1299 BMS_Data0 0;
BA_ "GenSigSendType" SG_ 1299 BMS_Data1 0;
BA_ "GenSigSendType" SG_ 1299 BMS_Data2 0;
BA_ "GenSigSendType" SG_ 1299 BMS_Data3 0;
BA_ "GenSigSendType" SG_ 1299 BMS_Data4 0;
BA_ "GenSigSendType" SG_ 1299 BMS_Data5 0;
BA_ "GenSigSendType" SG_ 1324 VCU_sourceID 0;
BA_ "GenSigSendType" SG_ 1324 VCU_CBV 0;
BA_ "GenSigSendType" SG_ 1324 VCU_Data0 0;
BA_ "GenSigSendType" SG_ 1324 VCU_Data1 0;
BA_ "GenSigSendType" SG_ 1324 VCU_Data2 0;
BA_ "GenSigSendType" SG_ 1324 VCU_Data3 0;
BA_ "GenSigSendType" SG_ 1324 VCU_Data4 0;
BA_ "GenSigSendType" SG_ 1324 VCU_Data5 0;
BA_ "GenSigSendType" SG_ 1341 PDU_DCDC_sourceID 0;
BA_ "GenSigSendType" SG_ 1341 PDU_DCDC_CBV 0;
BA_ "GenSigSendType" SG_ 1341 PDU_DCDC_Data0 0;
BA_ "GenSigSendType" SG_ 1341 PDU_DCDC_Data1 0;
BA_ "GenSigSendType" SG_ 1341 PDU_DCDC_Data2 0;
BA_ "GenSigSendType" SG_ 1341 PDU_DCDC_Data3 0;
BA_ "GenSigSendType" SG_ 1341 PDU_DCDC_Data4 0;
BA_ "GenSigSendType" SG_ 1341 PDU_DCDC_Data5 0;
BA_ "GenSigSendType" SG_ 1307 EDS_sourceID 0;
BA_ "GenSigSendType" SG_ 1307 EDS_CBV 0;
BA_ "GenSigSendType" SG_ 1307 EDS_Data0 0;
BA_ "GenSigSendType" SG_ 1307 EDS_Data1 0;
BA_ "GenSigSendType" SG_ 1307 EDS_Data2 0;
BA_ "GenSigSendType" SG_ 1307 EDS_Data3 0;
BA_ "GenSigSendType" SG_ 1307 EDS_Data4 0;
BA_ "GenSigSendType" SG_ 1307 EDS_Data5 0;
BA_ "GenSigSendType" SG_ 1311 EVCC_sourceID 0;
BA_ "GenSigSendType" SG_ 1311 EVCC_CBV 0;
BA_ "GenSigSendType" SG_ 1311 EVCC_Data0 0;
BA_ "GenSigSendType" SG_ 1311 EVCC_Data1 0;
BA_ "GenSigSendType" SG_ 1311 EVCC_Data2 0;
BA_ "GenSigSendType" SG_ 1311 EVCC_Data3 0;
BA_ "GenSigSendType" SG_ 1311 EVCC_Data4 0;
BA_ "GenSigSendType" SG_ 1311 EVCC_Data5 0;
BA_ "GenSigSendType" SG_ 1282 GW_sourceID 0;
BA_ "GenSigSendType" SG_ 1282 GW_CBV 0;
BA_ "GenSigSendType" SG_ 1282 GW_Data0 0;
BA_ "GenSigSendType" SG_ 1282 GW_Data1 0;
BA_ "GenSigSendType" SG_ 1282 GW_Data2 0;
BA_ "GenSigSendType" SG_ 1282 GW_Data3 0;
BA_ "GenSigSendType" SG_ 1282 GW_Data4 0;
BA_ "GenSigSendType" SG_ 1282 GW_Data5 0;
BA_ "GenSigSendType" SG_ 1691 EDS_DiagReqData0 0;
BA_ "GenSigSendType" SG_ 1691 EDS_DiagReqData1 0;
BA_ "GenSigSendType" SG_ 1691 EDS_DiagReqData2 0;
BA_ "GenSigSendType" SG_ 1691 EDS_DiagReqData3 0;
BA_ "GenSigSendType" SG_ 1691 EDS_DiagReqData4 0;
BA_ "GenSigSendType" SG_ 1691 EDS_DiagReqData5 0;
BA_ "GenSigSendType" SG_ 1691 EDS_DiagReqData6 0;
BA_ "GenSigSendType" SG_ 1691 EDS_DiagReqData7 0;
BA_ "GenSigSendType" SG_ 1563 EDS_DiagRespData0 0;
BA_ "GenSigSendType" SG_ 1563 EDS_DiagRespData1 0;
BA_ "GenSigSendType" SG_ 1563 EDS_DiagRespData2 0;
BA_ "GenSigSendType" SG_ 1563 EDS_DiagRespData3 0;
BA_ "GenSigSendType" SG_ 1563 EDS_DiagRespData4 0;
BA_ "GenSigSendType" SG_ 1563 EDS_DiagRespData5 0;
BA_ "GenSigSendType" SG_ 1563 EDS_DiagRespData6 0;
BA_ "GenSigSendType" SG_ 1563 EDS_DiagRespData7 0;
BA_ "GenSigSendType" SG_ 1791 GW_DiagFunctionalAddressingData0 0;
BA_ "GenSigSendType" SG_ 1791 GW_DiagFunctionalAddressingData1 0;
BA_ "GenSigSendType" SG_ 1791 GW_DiagFunctionalAddressingData2 0;
BA_ "GenSigSendType" SG_ 1791 GW_DiagFunctionalAddressingData3 0;
BA_ "GenSigSendType" SG_ 1791 GW_DiagFunctionalAddressingData4 0;
BA_ "GenSigSendType" SG_ 1791 GW_DiagFunctionalAddressingData5 0;
BA_ "GenSigSendType" SG_ 1791 GW_DiagFunctionalAddressingData6 0;
BA_ "GenSigSendType" SG_ 1791 GW_DiagFunctionalAddressingData7 0;
VAL_ 374 Rolling_Counter_0x176 15 "Invalid";
VAL_ 374 BMS_HVLinkVol_MEAS 65535 "Invalid";
VAL_ 374 BMS_HVPackVol_MEAS 65535 "Invalid";
VAL_ 533 Rolling_Counter_0x215 15 "Invalid";
VAL_ 533 BMS_HWCrash_Sts 1 "Crash " 0 "No Crash";
VAL_ 533 BMS_HVIL_STS 2 "short to ground" 1 "Open & short to battery" 0 "Closed";
VAL_ 533 BMS_IGN_Sts 1 "ON " 0 "OFF";
VAL_ 533 BMS_Sys_STS 8 "Invalid" 7 "Failure, unable to operate" 6 "BCU Sleep mode" 5 "Successful Power Down" 4 "Power Down process" 3 "Successful Power Down of HV" 2 "Successful High Voltage Power Up" 1 "Self-check passes, can be high-voltage" 0 "Initialization of power on, self-checking";
VAL_ 533 BMS_HVOnOff_STS 3 "Fail to HV on " 2 "HV On " 1 "Precharge " 0 "HV Off";
VAL_ 533 BMS_Balance_STS 1 "active " 0 "Inactive";
VAL_ 533 BMS_BatBalance_ERR 1 "normal " 0 "Error";
VAL_ 533 BMS_ISU_Status 3 "Level3(<100 Ohms/V)" 2 "Level2(<200 Ohms/V)" 1 "Level1 <500 Ohms/V ~ >200 Ohms/V" 0 "Normal (> 500 Ohms/V)";
VAL_ 533 BMS_ERR_LEV 7 "Battery locked -Reserved" 6 "Fault, needs Shutdown and Wakeup" 5 "Emergency off condition" 4 "Delayed power down with FTTI" 3 "Power down without FTTI" 2 "Limp Home" 1 " Warning (any warning in system)" 0 "No error";
VAL_ 533 BMS_HV_Sts 4 "AC Charging" 3 "DC Charging" 2 "HV ON" 1 "Precharge" 0 "HV Off";
VAL_ 885 Rolling_Counter_0x375 15 "Invalid";
VAL_ 885 BMS_MainPosRelay_ERR 1 "normal " 0 "Error";
VAL_ 885 BMS_MainPosRelay_STS 4 "stuck open" 3 "stuck closed" 2 "closed" 1 "open" 0 "reserved";
VAL_ 885 BMS_PreChgRelay_ERR 1 "normal " 0 "error";
VAL_ 885 BMS_PreChgRelay_STS 4 "stuck open" 3 "stuck closed" 2 "closed" 1 "open" 0 "reserved";
VAL_ 885 BMS_TotalNegRelay_STS 4 "stuck open" 3 "stuck closed" 2 "closed" 1 "open" 0 "reserved";
VAL_ 885 BMS_TotalNegRelay_ERR 1 "normal " 0 "Error";
VAL_ 840 EDS_bus_Volt_FWD 16383 "Invalid";
VAL_ 840 EDS_bus_Curr_FWD 65535 "Invalid";
VAL_ 840 EDS_HVIL_STS_FWD 3 "short to ground" 2 "short to battery" 1 "Open" 0 "Closed";
VAL_ 504 Rolling_Counter_0x1F8 15 "Invalid";
VAL_ 504 EDS_output_trq_FR 65535 "Invalid";
VAL_ 504 EDS_output_trqValid_FR 1 "valid" 0 "invalid";
VAL_ 504 EDS_Spd_FR 65535 "Invalid";
VAL_ 504 EDS_SpdValid_FR 1 "valid" 0 "invalid";
VAL_ 504 EDS_MotorDriveSts_FR 3 "Invaild" 2 "regen control" 1 "Drive control" 0 "Zero control";
VAL_ 504 EDS_Work_STS_FR 15 "invaild" 14 "power off" 13 "Failure" 12 "after run" 11 "shut down" 5 "HVReady" 4 "normal" 3 "precharge" 2 "standby" 1 "init" 0 "default";
VAL_ 504 EDS_powoff_req_FR 1 "(Request high voltage power down)" 0 "(No request)";
VAL_ 680 Rolling_Counter_0x2A8 15 "Invalid";
VAL_ 680 EDS_MotorSerialNum_FWD 0 "Invalid";
VAL_ 680 EDS_MinTrq_FWD 65535 "Invalid";
VAL_ 680 EDS_MaxTrq_FWD 65535 "Invalid";
VAL_ 568 EDS_MotTemp_MEAS_EDS_FWD 255 "Invalid";
VAL_ 568 EDS_MotTemp_MEAS_EDS_valid_FWD 1 "valid" 0 "invalid";
VAL_ 568 EDS_temp_FWD 255 "Invalid";
VAL_ 568 EDS_tempValid_FWD 1 "valid" 0 "invalid";
VAL_ 568 EDS_disxhg_st_FWD 3 "Finished Active Discharge" 2 "Failed Active Discharge" 1 "Active Discharge" 0 "No Active Discharge";
VAL_ 568 EDS_IGBTState_FWD 0 "FreeWheel" 1 "Up Bridge ASC" 2 "Down Bridge ASC" 3 "Normal Run";
VAL_ 568 EDS_DampingState_FWD 0 "Damping disable" 1 "Damping active";
VAL_ 568 EDS_CoolFlowrate_DMD_FWD 255 "Invalid";
VAL_ 1080 EDS_FailGrade_ERR_FWD 7 "Invaild" 6 "Invaild" 5 "Fifth Fault,Delayed power off" 4 "Forth Fault,ZeroTorque" 3 "Third Fault,Limp" 2 "Second Fault，Limited power" 1 "First-Level warning" 0 "No fault";
VAL_ 1080 EDS_MotOverTempAlarm_FWD 1 "Error" 0 "Normal";
VAL_ 1080 EDS_MotOverTempFault_FWD 1 "Error" 0 "Normal";
VAL_ 1080 EDS_MotTempSenFault_FWD 1 "Error" 0 "Normal";
VAL_ 1080 EDS_EDSOverTempUFault_FWD 1 "Error" 0 "Normal";
VAL_ 1080 EDS_EDSOverTempVFault_FWD 1 "Error" 0 "Normal";
VAL_ 1080 EDS_EDSOverTempWFault_FWD 1 "Error" 0 "Normal";
VAL_ 1080 EDS_EDSOverTempAlarm_FWD 1 "Error" 0 "Normal";
VAL_ 1080 EDS_TCoolantOvHi_FWD 1 "Error" 0 "Normal";
VAL_ 1080 EDS_EDSTempCmpAlarm_FWD 1 "Error" 0 "Normal";
VAL_ 1080 EDS_EDSPhaOvCurentHWFault_FWD 1 "Error" 0 "Normal";
VAL_ 1080 EDS_EDSphaOffCalFault_FWD 1 "Error" 0 "Normal";
VAL_ 1080 EDS_EDSOverIdcLnkAlarm_FWD 1 "Error" 0 "Normal";
VAL_ 1080 EDS_EDSHVOverVoltageAlarm_FWD 1 "Error" 0 "Normal";
VAL_ 1080 EDS_EDSHVOverVoltageFault_FWD 1 "Error" 0 "Normal";
VAL_ 1080 EDS_EDSHVUnderVoltageAlarm_FWD 1 "Error" 0 "Normal";
VAL_ 1080 EDS_EDSHVUnderVoltageFault_FWD 1 "Error" 0 "Normal";
VAL_ 1080 EDS_RunToDischaErr_FWD 1 "Error" 0 "Normal";
VAL_ 1080 EDS_12VOverVoltageAlarm_FWD 1 "Error" 0 "Normal";
VAL_ 1080 EDS_12VUnderVoltageAlarm_FWD 1 "Error" 0 "Normal";
VAL_ 1080 EDS_MotOverAlarm_FWD 1 "Error" 0 "Normal";
VAL_ 1080 EDS_MotOverFault_FWD 1 "Error" 0 "Normal";
VAL_ 1080 EDS_iDcLnkOvCLimFail_FWD 1 "Error" 0 "Normal";
VAL_ 1080 EDS_MotBlockedFault_FWD 1 "Error" 0 "Normal";
VAL_ 1080 EDS_RSLErr_FWD 1 "Error" 0 "Normal";
VAL_ 1080 EDS_MotTrqLimFault_FWD 1 "Error" 0 "Normal";
VAL_ 1080 EDS_ResolverOffsetAngle_FWD 1 "Error" 0 "Normal";
VAL_ 1080 EDS_EDSDisChgFault_FWD 1 "Error" 0 "Normal";
VAL_ 1080 EDS_IGBTFault_FWD 1 "Error" 0 "Normal";
VAL_ 1080 EDS_CANBusoffFault_FWD 1 "Error" 0 "Normal";
VAL_ 1080 EDS_TDrvBoardOvHiWarn_FWD 1 "Error" 0 "Normal";
VAL_ 1080 EDS_TIGBTOvHiFault_FWD 1 "Error" 0 "Normal";
VAL_ 1080 EDS_TIGBTOvHiWarn_FWD 1 "Error" 0 "Normal";
VAL_ 1080 EDS_IOHWABSampFail_FWD 1 "Error" 0 "Normal";
VAL_ 1080 EDS_EDSOpenFault_FWD 1 "Error" 0 "Normal";
VAL_ 1080 EDS_MotorOpenFault_FWD 1 "Error" 0 "Normal";
VAL_ 1080 EDS_EmacBlkdWarn_FWD 1 "Error" 0 "Normal";
VAL_ 1080 EDS_VerMatchFailureErr_FWD 1 "Error" 0 "Normal";
VAL_ 1080 EDS_DiashCirNoPsblErr_FWD 1 "Error" 0 "Normal";
VAL_ 1080 EDS_OperOutdRngErr_FWD 1 "Error" 0 "Normal";
VAL_ 1080 EDS_PhaseLossFaultErr_FWD 1 "Error" 0 "Normal";
VAL_ 1080 EDS_CPLDFault_FWD 1 "Error" 0 "Normal";
VAL_ 1080 EDS_CPLDFaultBaseSpd_FWD 1 "Error" 0 "Normal";
VAL_ 1080 EDS_IOHWABNen33Fail_FWD 1 "Error" 0 "Normal";
VAL_ 1080 EDS_HvMcuSlightFault_RWD 1 "Error" 0 "Normal";
VAL_ 1080 EDS_HvMcuSevFault_FWD 1 "Error" 0 "Normal";
VAL_ 1080 EDS_EDSPhaSampHWFault_FWD 1 "Error" 0 "Normal";
VAL_ 1080 EDS_IsOvHiErr_FWD 1 "Error" 0 "Normal";
VAL_ 1080 EDS_CanRollingCounterErr_FWD 1 "Error" 0 "Normal";
VAL_ 1080 EDS_CanTimeoutErr_FWD 1 "Error" 0 "Normal";
VAL_ 1080 EDS_CrashFault_FWD 1 "Error" 0 "Normal";
VAL_ 553 Rolling_Counter_0x229 15 "Invalid";
VAL_ 553 VCU_EDS_TargetTqMin_FWD 1023 "Invalid";
VAL_ 553 VCU_EDS_StsModeReq_FWD 15 "invaild" 14 "power off" 13 "Failure" 12 "after run" 11 "shut down" 5 "HVReady" 4 "normal" 3 "precharge" 2 "standby" 1 "init" 0 "default";
VAL_ 553 VCU_EDS_demtrq_FWD 4095 "Invalid";
VAL_ 553 VCU_EDS_demtrqValid_FWD 0 "Valid" 1 "Invalid";
VAL_ 553 VCU_EDS_TargetTqMax_FWD 1023 "Invalid";
VAL_ 553 VCU_EDS_CreepFlg_FWD 1 "Enable" 0 "Disable";
VAL_ 553 VCU_EDS_HILLHoldFlg_FWD 1 "Enable" 0 "Disable";
VAL_ 937 VCU_PTC_RelaySts 1 "close" 0 "open";
VAL_ 937 VCU_EACEnbReq 1 "Enable" 0 "Disable";
VAL_ 937 VCU_EACAllowedPower 1023 "Invalid";
VAL_ 937 VCU_EAC_CompSpdReq 16383 "Invaild";
VAL_ 524 Rolling_Counter_0x20C 15 "Invalid";
VAL_ 524 IPC_ODO 1048575 "Invalid";
VAL_ 703 IPC_TripA 65535 "Invalid";
VAL_ 703 IPC_AverageSpeedTripA 4095 "Invalid";
VAL_ 703 IPC_AverageConsumptionTripA 1023 "Invalid";
VAL_ 703 IPC_ParkBrakeSts 3 "Invalid" 2 "Reserved" 1 "Applied" 0 "Released";
VAL_ 703 IPC_VehSpd 32767 "Invalid";
VAL_ 1087 IPC_Sec 63 "Invalid";
VAL_ 1087 IPC_Min 63 "Invalid";
VAL_ 1087 IPC_Hour 31 "Invalid";
VAL_ 1087 IPC_Day 31 "Invalid";
VAL_ 1087 IPC_Month 15 "Invalid";
VAL_ 1087 IPC_Year 255 "Invalid";
VAL_ 1087 IPC_SelfCheckStatus 1 "self-check finish" 0 "self-checking";
VAL_ 1074 Rolling_Counter_0x432 15 "Invalid";
VAL_ 1074 MHU_FOTA_State 0 "INIT" 1 "NORMAL" 2 "FOTA FLASHING" 3 "FOTA-SUSPENDED" 4 "FAIL-SAFE-ERROR" 5 "SHUTDOWN" 6 "REMOTE DIAGNOSTICS" 7 "Invalid";
VAL_ 811 CCU_TemperatureGearSts 63 "Invalid" 16 "level 8" 15 "level 7" 14 "level 6" 13 "level 5" 12 "level 4" 11 "level 3" 10 "level 2" 9 "level 1" 8 "level 8" 7 "level 7" 6 "level 6" 5 "level 5" 4 "level 4" 3 "level 3" 2 "level 2" 1 "level 1" 0 "Inactive";
VAL_ 811 CCU_BlowMode_Sts 7 "Invalid" 6 "Reserve" 4 "Foot and window" 3 "Foot" 2 "Foot and Face" 1 "Face" 0 "OFF";
VAL_ 811 CCU_Circulation_Sts 1 "Internal circulation" 0 "Outer circulation";
VAL_ 811 CCU_AC_Req 3 "Invalid" 2 "Reserved" 1 "Requset" 0 "No requset";
VAL_ 811 CCU_AC_Sts 1 "ON" 0 "OFF";
VAL_ 811 CCU_BlowerLevelSts 8 "level 8" 7 "level 7" 6 "level 6" 5 "level 5" 4 "level 4" 3 "level 3" 2 "level 2" 1 "level 1" 0 "OFF";
VAL_ 811 CCU_FrontDefrostSts 1 "On" 0 "Off";
VAL_ 811 CCU_PTC_Req 3 "Invalid" 2 "Reserved" 1 "Requset" 0 "No requset";
VAL_ 811 CCU_PTC_Temperature 1023 "Invaild";
VAL_ 811 CCU_CompSpdMEAS_Comp 8191 "Invalid";
VAL_ 811 CCU_PollutionSts 1 "ON" 0 "OFF";
VAL_ 811 CCU_ExternalTemperature 255 "Invaild";
VAL_ 811 CCU_evaporator_Temperature 31 "Invalid";
VAL_ 811 CCU_ExternalTemperatureFailSts 1 "invalid" 0 "valid";
VAL_ 274 Rolling_Counter_0x112 15 "Invalid";
VAL_ 274 STAT_Terminal 7 "Signal invalid" 6 "Reserved" 5 "Reserved" 4 "SW update OTA (Not used in VFe34)" 3 "Engine start (eMotor running)" 2 "ON (Driver Present)" 1 "ACC (Park)" 0 "OFF(Comfort Enable)";
VAL_ 274 STAT_CL30s_L_Reserved 3 "Signal invalid" 2 "Failure" 1 "ON" 0 "OFF";
VAL_ 266 Rolling_Counter_0x10a 15 "Invalid";
VAL_ 266 BCM_LVTop_up 1 "start Top up" 0 "stop Top up";
VAL_ 133 Rolling_Counter_0x85 15 "Invalid";
VAL_ 133 ACM_Crash_Sts 3 "Invalid Value" 2 "Invalid Value" 1 "Crash_Detected" 0 "No_Event";
VAL_ 133 ACM_Airbag_Deployment_Status 3 "Invalid Value" 2 "Invalid Value" 1 "Airbag_Deployment" 0 "No_Airbag_Deployment";
VAL_ 133 ACM_Crash_Intensity 7 "Invalid_Value" 6 "Invalid_Value" 5 "Invalid_Value" 4 "Invalid_Value" 3 "Crash_Intensity_3" 2 "Crash_Intensity_2" 1 "Crash_Intensity_1" 0 "No_Crash";
VAL_ 133 ACM_Front_Crash 3 "Invalid Value" 2 "Invalid Value" 1 "Front_Crash_Detected" 0 "No_Event";
VAL_ 133 ACM_DriverSide_Crash 3 "Invalid Value" 2 "Invalid Value" 1 "Driverside_Crash_Detected" 0 "No_Event";
VAL_ 133 ACM_PassSide_Crash 3 "Invalid Value" 2 "Invalid Value" 1 "PassSide_Crash_Detected" 0 "No_Event";
VAL_ 133 ACM_Rear_Crash 3 "Invalid Value" 2 "Invalid Value" 1 "Rear_Crash_Detected" 0 "No_Event";
VAL_ 133 ACM_Rollover_Crash 3 "Invalid Value" 2 "Invalid Value" 1 "Rollover_Crash_Detected" 0 "No_Event";
VAL_ 834 Rolling_Counter_0x342 15 "Invalid";
VAL_ 834 ABS_LRWhlSpdRaw 32767 "Invalid";
VAL_ 834 ABS_LRWhlSpdRawValid 1 "Valid" 0 "Invalid";
VAL_ 834 ABS_RRWhlSpdRaw 32767 "Invalid";
VAL_ 834 ABS_RRWhlSpdRawValid 1 "Valid" 0 "Invalid";
VAL_ 834 ABS_VehSpd 32767 "Invalid";
VAL_ 834 ABS_VehSpdValid 1 "Valid" 0 "Invalid";
VAL_ 149 RollingCounter_0x95 15 "Invalid";
VAL_ 149 ABS_Active 3 "Signal invalid" 2 "Reserved" 1 "Active" 0 "Inactive";
VAL_ 149 ASR_Active 3 "Signal invalid" 2 "Reserved" 1 "Active" 0 "Inactive";
